VERSION ""

NS_ :

BS_:

BU_: ETH

BO_ 1824 DAS_debug: 12 Vector__XXX
 SG_ DAS_debugMultiplexer M : 0|8@1+ (1,0) [0|0] "" Vector__XXX
 SG_ DAS_ACC_Control_targetID m28 : 8|4@1+ (1,0) [0|0] "" Vector__XXX
 SG_ DAS_ACC_Restrict_targetID m29 : 8|4@1+ (1,0) [0|0] "" Vector__XXX
 SG_ DAS_ACC_Target6_dist m27 : 8|10@1+ (0.2,0) [0|0] "" Vector__XXX
 SG_ DAS_ACC_camCIPVRadObjID m21 : 8|8@1+ (1,0) [0|0] "" Vector__XXX
 SG_ DAS_ACC_intState m20 : 8|4@1+ (1,0) [0|0] "" Vector__XXX
 SG_ DAS_ACC_tgt_cipv2_dist m23 : 8|10@1+ (0.2,0) [0|0] "" Vector__XXX
 SG_ DAS_ACC_tgt_cipv_dist m22 : 8|10@1+ (0.2,0) [0|0] "" Vector__XXX
 SG_ DAS_ACC_tgt_cutin_dist m26 : 8|10@1+ (0.2,0) [0|0] "" Vector__XXX
 SG_ DAS_ACC_tgt_mcvl_dist m24 : 8|10@1+ (0.2,0) [0|0] "" Vector__XXX
 SG_ DAS_ACC_tgt_mcvr_dist m25 : 8|10@1+ (0.2,0) [0|0] "" Vector__XXX
 SG_ DAS_FCM_CIPV_distance m30 : 8|12@1+ (0.0625,0) [0|0] "" Vector__XXX
 SG_ DAS_FCM_DBG_cam_dist m35 : 8|12@1+ (0.0625,0) [0|0] "" Vector__XXX
 SG_ DAS_FCM_MCP_distance m31 : 8|12@1+ (0.0625,0) [0|0] "" Vector__XXX
 SG_ DAS_FCM_SL_distance m32 : 8|12@1+ (0.0625,0) [0|0] "" Vector__XXX
 SG_ DAS_FCM_TA_collisionStage m33 : 8|2@1+ (1,0) [0|0] "" Vector__XXX
 SG_ DAS_HmViewRangeActivationCtr m41 : 8|7@1+ (1,0) [0|0] "" Vector__XXX
 SG_ DAS_IDF_checkSensors m36 : 8|1@1+ (1,0) [0|0] "" Vector__XXX
 SG_ DAS_LCM_CIPV_ax m38 : 8|8@1- (0.1,0) [0|0] "" Vector__XXX
 SG_ DAS_LCM_CIPV_dx m37 : 8|12@1+ (0.0625,0) [0|0] "" Vector__XXX
 SG_ DAS_LCM_driver_reaction_time m39 : 8|4@1+ (0.1,0.8) [0|0] "" Vector__XXX
 SG_ DAS_LC_SteeringOffsetEstimate m42 : 8|8@1- (0.1,0) [0|0] "" Vector__XXX
 SG_ DAS_LC_VirtualLaneViewRange m40 : 8|10@1+ (0.5,0) [0|0] "" Vector__XXX
 SG_ DAS_PMM_ussConfidence m11 : 8|8@1+ (1,0) [0|0] "" Vector__XXX
 SG_ DAS_Planner_viewRange m46 : 8|9@1+ (0.5,0) [0|0] "" Vector__XXX
 SG_ DAS_SCA_state m45 : 8|3@1+ (1,0) [0|0] "" Vector__XXX
 SG_ DAS_SP_cMin m7 : 8|8@1+ (0.0025,-0.32) [0|0] "" Vector__XXX
 SG_ DAS_SP_sprecordX m9 : 8|12@1+ (0.01,-20.48) [0|0] "" Vector__XXX
 SG_ DAS_SP_vehPosX m8 : 8|12@1+ (0.01,-20.48) [0|0] "" Vector__XXX
 SG_ DAS_Stop_Sign_dist m4 : 8|11@1+ (0.1,-50) [0|0] "" Vector__XXX
 SG_ DAS_VL_HPP_rejectCounter m50 : 8|1@1+ (1,0) [0|0] "" Vector__XXX
 SG_ DAS_VL_M_LL_crossCheck m51 : 8|1@1+ (1,0) [0|0] "" Vector__XXX
 SG_ DAS_VL_exitChecks_EGO_LNE_LEFT m52 : 8|1@1+ (1,0) [0|0] "" Vector__XXX
 SG_ DAS_VWall_Left_ultra_dist m43 : 8|9@1+ (0.01,0) [0|0] "" Vector__XXX
 SG_ DAS_VWall_Right_type m44 : 8|3@1+ (1,0) [0|0] "" Vector__XXX
 SG_ DAS_apcIntState m6 : 8|4@1+ (1,0) [0|0] "" Vector__XXX
 SG_ DAS_autoWipersNetwork m60 : 8|16@1+ (0.01,0) [0|0] "" Vector__XXX
 SG_ DAS_autofixStatus m1 : 8|2@1+ (1,0) [0|0] "" Vector__XXX
 SG_ DAS_csa_accel_max m47 : 8|8@1+ (0.08,-10.24) [0|0] "" Vector__XXX
 SG_ DAS_csa_internal_state m48 : 8|4@1+ (1,0) [0|0] "" Vector__XXX
 SG_ DAS_dbg_msg_count m10 : 8|8@1+ (1,0) [0|0] "" Vector__XXX
 SG_ DAS_eyeQMode m0 : 8|8@1+ (1,0) [0|0] "" Vector__XXX
 SG_ DAS_freespaceLeftC0 m2 : 8|8@1+ (0.1,-12.8) [0|0] "" Vector__XXX
 SG_ DAS_highestSeqRcvd m3 : 8|12@1+ (1,0) [0|0] "" Vector__XXX
 SG_ DAS_i2c_dev_reg m12 : 8|8@1+ (1,0) [0|0] "" Vector__XXX
 SG_ DAS_tbt_filtered m5 : 8|12@1+ (0.01,-20.5) [0|0] "" Vector__XXX
 SG_ DAS_IDF_checkClass m36 : 9|1@1+ (1,0) [0|0] "" Vector__XXX
 SG_ DAS_VL_M_RL_crossCheck m51 : 9|1@1+ (1,0) [0|0] "" Vector__XXX
 SG_ DAS_VL_exitChecks_EGO_LNE_RGHT m52 : 9|1@1+ (1,0) [0|0] "" Vector__XXX
 SG_ DAS_FCM_TA_collisionOverlap m33 : 10|6@1+ (0.1,0) [0|0] "" Vector__XXX
 SG_ DAS_IDF_checkOverlap m36 : 10|1@1+ (1,0) [0|0] "" Vector__XXX
 SG_ DAS_VL_M_HPP_crossCheck m51 : 10|1@1+ (1,0) [0|0] "" Vector__XXX
 SG_ DAS_VL_exitChecks_BLINKER_LEFT m52 : 10|1@1+ (1,0) [0|0] "" Vector__XXX
 SG_ DAS_IDF_checkTimeToCollision m36 : 11|1@1+ (1,0) [0|0] "" Vector__XXX
 SG_ DAS_VL_M_NAV_crossCheck m51 : 11|1@1+ (1,0) [0|0] "" Vector__XXX
 SG_ DAS_VL_exitChecks_BLINKER_RGHT m52 : 11|1@1+ (1,0) [0|0] "" Vector__XXX
 SG_ DAS_ACC_Control_sl_d m28 : 12|10@1+ (0.2,0) [0|0] "" Vector__XXX
 SG_ DAS_ACC_Restrict_sl_d m29 : 12|10@1+ (0.2,0) [0|0] "" Vector__XXX
 SG_ DAS_ACC_camCIPVStatus m20 : 12|3@1+ (1,0) [0|0] "" Vector__XXX
 SG_ DAS_IDF_checkTargetProbability m36 : 12|1@1+ (1,0) [0|0] "" Vector__XXX
 SG_ DAS_LCM_override_stw_angle m39 : 12|1@1+ (1,0) [0|0] "" Vector__XXX
 SG_ DAS_SCA_angleActive m45 : 12|1@1+ (1,0) [0|0] "" Vector__XXX
 SG_ DAS_SP_distance m6 : 12|12@1+ (1,0) [0|0] "" Vector__XXX
 SG_ DAS_VL_M_V1_crossCheck m51 : 12|1@1+ (1,0) [0|0] "" Vector__XXX
 SG_ DAS_calType m1 : 12|4@1+ (1,0) [0|0] "" Vector__XXX
 SG_ DAS_pp_lanechange_fwdObst m48 : 12|1@1+ (1,0) [0|0] "" Vector__XXX
 SG_ DAS_IDF_checkSteeringAvoidance m36 : 13|1@1+ (1,0) [0|0] "" Vector__XXX
 SG_ DAS_LCM_override_stw_rate m39 : 13|1@1+ (1,0) [0|0] "" Vector__XXX
 SG_ DAS_SCA_egoRightOfCenter m45 : 13|1@1+ (1,0) [0|0] "" Vector__XXX
 SG_ DAS_VL_M_V2_crossCheck m51 : 13|1@1+ (1,0) [0|0] "" Vector__XXX
 SG_ DAS_VL_leftFsParallelLeftLane m50 : 13|1@1+ (1,0) [0|0] "" Vector__XXX
 SG_ DAS_pp_lanechange_inputsValid m48 : 13|1@1+ (1,0) [0|0] "" Vector__XXX
 SG_ DAS_IDF_checkBrakingAvoidance m36 : 14|1@1+ (1,0) [0|0] "" Vector__XXX
 SG_ DAS_LCM_override_accelerator m39 : 14|1@1+ (1,0) [0|0] "" Vector__XXX
 SG_ DAS_SCA_egoLeftOfCenter m45 : 14|1@1+ (1,0) [0|0] "" Vector__XXX
 SG_ DAS_VL_M_V3_crossCheck m51 : 14|1@1+ (1,0) [0|0] "" Vector__XXX
 SG_ DAS_VL_leftFsParallelRightLane m50 : 14|1@1+ (1,0) [0|0] "" Vector__XXX
 SG_ DAS_pp_lanechange_side m48 : 14|2@1+ (1,0) [0|0] "" Vector__XXX
 SG_ DAS_ACC_radCIPVStatus m20 : 15|3@1+ (1,0) [0|0] "" Vector__XXX
 SG_ DAS_IDF_checkEgoSpeed m36 : 15|1@1+ (1,0) [0|0] "" Vector__XXX
 SG_ DAS_LCM_override_brake m39 : 15|1@1+ (1,0) [0|0] "" Vector__XXX
 SG_ DAS_SCA_egoMovingLeft m45 : 15|1@1+ (1,0) [0|0] "" Vector__XXX
 SG_ DAS_SYNC_EyeQGlobalFrameNum m100 : 15|32@0+ (1,0) [0|0] "" Vector__XXX
 SG_ DAS_VL_M_V4_crossCheck m51 : 15|1@1+ (1,0) [0|0] "" Vector__XXX
 SG_ DAS_VL_rightFsParallelLeftLane m50 : 15|1@1+ (1,0) [0|0] "" Vector__XXX
 SG_ DAS_ACC_camCIPVRadMatchConf m21 : 16|4@1+ (1,0) [0|0] "" Vector__XXX
 SG_ DAS_FCM_state m33 : 16|8@1+ (1,0) [0|0] "" Vector__XXX
 SG_ DAS_HmGeneralActivationCtr m41 : 16|7@1+ (1,0) [0|0] "" Vector__XXX
 SG_ DAS_IDF_timeToCollision m36 : 16|8@1+ (10,0) [0|0] "" Vector__XXX
 SG_ DAS_LCM_CIPV_ay m38 : 16|8@1- (0.1,0) [0|0] "" Vector__XXX
 SG_ DAS_LCM_override_blinker m39 : 16|1@1+ (1,0) [0|0] "" Vector__XXX
 SG_ DAS_PMM_ussDistance m11 : 16|8@1+ (1,0) [0|0] "" Vector__XXX
 SG_ DAS_SCA_TWC_Left m45 : 16|8@1+ (0.01,0) [0|0] "" Vector__XXX
 SG_ DAS_SP_cMax m7 : 16|8@1+ (0.0025,-0.32) [0|0] "" Vector__XXX
 SG_ DAS_VL_M_V5_crossCheck m51 : 16|1@1+ (1,0) [0|0] "" Vector__XXX
 SG_ DAS_VL_rightFsParallelRightLane m50 : 16|1@1+ (1,0) [0|0] "" Vector__XXX
 SG_ DAS_VWall_Right_ultra_dist m44 : 16|9@1+ (0.01,0) [0|0] "" Vector__XXX
 SG_ DAS_absoluteFrame m0 : 16|32@1+ (1,0) [0|0] "" Vector__XXX
 SG_ DAS_autofixHorizon m1 : 16|8@1- (1,0) [0|0] "" Vector__XXX
 SG_ DAS_csa_predictedLatAccel m47 : 16|8@1+ (0.08,-10.24) [0|0] "" Vector__XXX
 SG_ DAS_dbg_image_data m10 : 16|48@1+ (1,0) [0|0] "" Vector__XXX
 SG_ DAS_freespaceLeftC1 m2 : 16|8@1+ (0.0016,-0.2) [0|0] "" Vector__XXX
 SG_ DAS_i2c_dev_data m12 : 16|8@1+ (1,0) [0|0] "" Vector__XXX
 SG_ DAS_pp_laneChange_destLanesValid m48 : 16|1@1+ (1,0) [0|0] "" Vector__XXX
 SG_ DAS_pp_offset_objectStateLeft m49 : 16|3@1+ (1,0) [0|0] "" Vector__XXX
 SG_ DAS_LCM_override_accelerator_aeb m39 : 17|1@1+ (1,0) [0|0] "" Vector__XXX
 SG_ DAS_Planner_internalstate m46 : 17|4@1+ (1,0) [0|0] "" Vector__XXX
 SG_ DAS_VL_LL_RL_crossCheck m51 : 17|1@1+ (1,0) [0|0] "" Vector__XXX
 SG_ DAS_VL_LL_quality m50 : 17|1@1+ (1,0) [0|0] "" Vector__XXX
 SG_ DAS_pp_laneChange_egoLaneValid m48 : 17|1@1+ (1,0) [0|0] "" Vector__XXX
 SG_ DAS_ACC_Target6_camID m27 : 18|6@1+ (1,0) [0|0] "" Vector__XXX
 SG_ DAS_ACC_radObstacleRelevant m20 : 18|1@1+ (1,0) [0|0] "" Vector__XXX
 SG_ DAS_ACC_tgt_cipv2_camID m23 : 18|6@1+ (1,0) [0|0] "" Vector__XXX
 SG_ DAS_ACC_tgt_cipv_camID m22 : 18|6@1+ (1,0) [0|0] "" Vector__XXX
 SG_ DAS_ACC_tgt_cutin_camID m26 : 18|6@1+ (1,0) [0|0] "" Vector__XXX
 SG_ DAS_ACC_tgt_mcvl_camID m24 : 18|6@1+ (1,0) [0|0] "" Vector__XXX
 SG_ DAS_ACC_tgt_mcvr_camID m25 : 18|6@1+ (1,0) [0|0] "" Vector__XXX
 SG_ DAS_LCM_override_brake_aeb m39 : 18|1@1+ (1,0) [0|0] "" Vector__XXX
 SG_ DAS_LC_VirtualLaneWidth m40 : 18|8@1+ (0.025,0) [0|0] "" Vector__XXX
 SG_ DAS_VL_LL_HPP_crossCheck m51 : 18|1@1+ (1,0) [0|0] "" Vector__XXX
 SG_ DAS_VL_RL_quality m50 : 18|1@1+ (1,0) [0|0] "" Vector__XXX
 SG_ DAS_pp_laneChange_anyObstacle m48 : 18|1@1+ (1,0) [0|0] "" Vector__XXX
 SG_ DAS_ACC_pedestrianStatus m20 : 19|2@1+ (1,0) [0|0] "" Vector__XXX
 SG_ DAS_LCM_aeb_abs_accel m39 : 19|1@1+ (1,0) [0|0] "" Vector__XXX
 SG_ DAS_Stop_Sign_detected m4 : 19|1@1+ (1,0) [0|0] "" Vector__XXX
 SG_ DAS_VL_HPP_quality m50 : 19|1@1+ (1,0) [0|0] "" Vector__XXX
 SG_ DAS_VL_LL_NAV_crossCheck m51 : 19|1@1+ (1,0) [0|0] "" Vector__XXX
 SG_ DAS_pp_laneChange_closeObstacle m48 : 19|1@1+ (1,0) [0|0] "" Vector__XXX
 SG_ DAS_pp_offset_objectStateRight m49 : 19|3@1+ (1,0) [0|0] "" Vector__XXX
 SG_ DAS_ACC_camCIPVClass m21 : 20|4@1+ (1,0) [0|0] "" Vector__XXX
 SG_ DAS_FCM_CIPV_latDistance m30 : 20|12@1- (0.05,0) [0|0] "" Vector__XXX
 SG_ DAS_FCM_DBG_cam_relvel m35 : 20|12@1+ (0.0625,-128) [0|0] "" Vector__XXX
 SG_ DAS_FCM_MCP_latDistance m31 : 20|12@1- (0.05,0) [0|0] "" Vector__XXX
 SG_ DAS_FCM_SL_latDistance m32 : 20|12@1- (0.05,0) [0|0] "" Vector__XXX
 SG_ DAS_LCM_CIPV_dy m37 : 20|12@1- (0.05,0) [0|0] "" Vector__XXX
 SG_ DAS_LCM_aeb_overlap m39 : 20|1@1+ (1,0) [0|0] "" Vector__XXX
 SG_ DAS_SP_sprecordY m9 : 20|12@1+ (0.01,-20.48) [0|0] "" Vector__XXX
 SG_ DAS_SP_vehPosY m8 : 20|12@1+ (0.01,-20.48) [0|0] "" Vector__XXX
 SG_ DAS_Stop_Sign_warning m4 : 20|1@1+ (1,0) [0|0] "" Vector__XXX
 SG_ DAS_VL_LL_V1_crossCheck m51 : 20|1@1+ (1,0) [0|0] "" Vector__XXX
 SG_ DAS_VL_NAV_quality m50 : 20|1@1+ (1,0) [0|0] "" Vector__XXX
 SG_ DAS_errorFrameNum m3 : 20|12@1+ (1,0) [0|0] "" Vector__XXX
 SG_ DAS_pp_laneChange_LC_healthy m48 : 20|1@1+ (1,0) [0|0] "" Vector__XXX
 SG_ DAS_ACC_drivingOnHighway m20 : 21|1@1+ (1,0) [0|0] "" Vector__XXX
 SG_ DAS_LCM_aeb_current_accel m39 : 21|1@1+ (1,0) [0|0] "" Vector__XXX
 SG_ DAS_Planner_externalstate m46 : 21|4@1+ (1,0) [0|0] "" Vector__XXX
 SG_ DAS_TFL_jnc_status m4 : 21|3@1+ (1,0) [0|0] "" Vector__XXX
 SG_ DAS_VL_LL_V2_crossCheck m51 : 21|1@1+ (1,0) [0|0] "" Vector__XXX
 SG_ DAS_VL_V1_quality m50 : 21|1@1+ (1,0) [0|0] "" Vector__XXX
 SG_ DAS_pp_laneChange_blinkerCheck m48 : 21|1@1+ (1,0) [0|0] "" Vector__XXX
 SG_ DAS_ACC_Control_ve_d m28 : 22|10@1+ (0.05,0) [0|0] "" Vector__XXX
 SG_ DAS_ACC_Restrict_ve_d m29 : 22|10@1+ (0.05,0) [0|0] "" Vector__XXX
 SG_ DAS_LCM_aeb_delayed_accel m39 : 22|1@1+ (1,0) [0|0] "" Vector__XXX
 SG_ DAS_VL_LL_V3_crossCheck m51 : 22|1@1+ (1,0) [0|0] "" Vector__XXX
 SG_ DAS_VL_WidthMeasType m50 : 22|3@1+ (1,0) [0|0] "" Vector__XXX
 SG_ DAS_pp_offset_activeLeft m49 : 22|1@1+ (1,0) [0|0] "" Vector__XXX
 SG_ DAS_torque_filt_0p05Hz m48 : 22|12@1+ (0.01,-20.5) [0|0] "" Vector__XXX
 SG_ DAS_HmSecondaryVlInput m41 : 23|1@1+ (1,0) [0|0] "" Vector__XXX
 SG_ DAS_LCM_aeb_evading_dist m39 : 23|1@1+ (1,0) [0|0] "" Vector__XXX
 SG_ DAS_VL_LL_V4_crossCheck m51 : 23|1@1+ (1,0) [0|0] "" Vector__XXX
 SG_ DAS_pp_offset_activeRight m49 : 23|1@1+ (1,0) [0|0] "" Vector__XXX
 SG_ DAS_ACC_Target6_speed m27 : 24|8@1+ (0.2,-5) [0|0] "" Vector__XXX
 SG_ DAS_ACC_camCIPVRelevancy m21 : 24|4@1+ (1,0) [0|0] "" Vector__XXX
 SG_ DAS_ACC_tgt_cipv2_speed m23 : 24|8@1+ (0.2,-5) [0|0] "" Vector__XXX
 SG_ DAS_ACC_tgt_cipv_speed m22 : 24|8@1+ (0.2,-5) [0|0] "" Vector__XXX
 SG_ DAS_ACC_tgt_cutin_speed m26 : 24|8@1+ (0.2,-5) [0|0] "" Vector__XXX
 SG_ DAS_ACC_tgt_mcvl_speed m24 : 24|8@1+ (0.2,-5) [0|0] "" Vector__XXX
 SG_ DAS_ACC_tgt_mcvr_speed m25 : 24|8@1+ (0.2,-5) [0|0] "" Vector__XXX
 SG_ DAS_FCM_TA_rstCollStRsn m33 : 24|8@1+ (1,0) [0|0] "" Vector__XXX
 SG_ DAS_FCM_TA_stage2Checks m34 : 24|8@1+ (1,0) [0|0] "" Vector__XXX
 SG_ DAS_IDF_objectClass m36 : 24|3@1+ (1,0) [0|0] "" Vector__XXX
 SG_ DAS_LCM_CIPV_id m38 : 24|8@1+ (1,0) [0|0] "" Vector__XXX
 SG_ DAS_LCM_aeb_rel_vel m39 : 24|1@1+ (1,0) [0|0] "" Vector__XXX
 SG_ DAS_LC_PathFollowerAngle m42 : 24|13@1- (0.1,0) [0|0] "" Vector__XXX
 SG_ DAS_PF_Navigation_STW m41 : 24|13@1+ (0.1,-409.6) [0|0] "" Vector__XXX
 SG_ DAS_PMM_radarConfidence m11 : 24|8@1+ (1,0) [0|0] "" Vector__XXX
 SG_ DAS_SCA_TWC_Right m45 : 24|8@1+ (0.01,0) [0|0] "" Vector__XXX
 SG_ DAS_SP_instruction m6 : 24|4@1+ (1,0) [0|0] "" Vector__XXX
 SG_ DAS_SP_interCMin m7 : 24|8@1+ (0.0025,-0.32) [0|0] "" Vector__XXX
 SG_ DAS_TFL_jnc_dist m4 : 24|10@1+ (0.25,-50) [0|0] "" Vector__XXX
 SG_ DAS_VL_LL_V5_crossCheck m51 : 24|1@1+ (1,0) [0|0] "" Vector__XXX
 SG_ DAS_autoWipersPerMinute m60 : 24|8@1+ (1,0) [0|0] "" Vector__XXX
 SG_ DAS_autofixYaw m1 : 24|8@1- (1,0) [0|0] "" Vector__XXX
 SG_ DAS_csa_filteredCurvature m47 : 24|16@1- (1e-06,0) [0|0] "" Vector__XXX
 SG_ DAS_freespaceRightC0 m2 : 24|8@1+ (0.1,-12.8) [0|0] "" Vector__XXX
 SG_ DAS_i2c_cmd_idx m12 : 24|16@1+ (1,0) [0|0] "" Vector__XXX
 SG_ DAS_pp_offset_offsetObjectLeft m49 : 24|8@1- (0.01,0) [0|0] "" Vector__XXX
 SG_ DAS_LCM_jerk_abs_accel m39 : 25|1@1+ (1,0) [0|0] "" Vector__XXX
 SG_ DAS_VL_RL_HPP_crossCheck m51 : 25|1@1+ (1,0) [0|0] "" Vector__XXX
 SG_ DAS_VL_Reinitialized m50 : 25|1@1+ (1,0) [0|0] "" Vector__XXX
 SG_ DAS_ACC_Ego_speed m20 : 26|10@1+ (0.05,0) [0|0] "" Vector__XXX
 SG_ DAS_LCM_jerk_overlap m39 : 26|1@1+ (1,0) [0|0] "" Vector__XXX
 SG_ DAS_LC_AutopilotInternalState m40 : 26|4@1+ (1,0) [0|0] "" Vector__XXX
 SG_ DAS_VL_LL_rejectQuality m50 : 26|1@1+ (1,0) [0|0] "" Vector__XXX
 SG_ DAS_VL_RL_NAV_crossCheck m51 : 26|1@1+ (1,0) [0|0] "" Vector__XXX
 SG_ DAS_IDF_predictedImpactVelocity m36 : 27|7@1+ (0.5,0) [0|0] "" Vector__XXX
 SG_ DAS_LCM_jerk_current_accel m39 : 27|1@1+ (1,0) [0|0] "" Vector__XXX
 SG_ DAS_VL_LL_rejectType m50 : 27|1@1+ (1,0) [0|0] "" Vector__XXX
 SG_ DAS_VL_RL_V1_crossCheck m51 : 27|1@1+ (1,0) [0|0] "" Vector__XXX
 SG_ DAS_ACC_camCIPVLane m21 : 28|4@1+ (1,0) [0|0] "" Vector__XXX
 SG_ DAS_LCM_jerk_delayed_accel m39 : 28|1@1+ (1,0) [0|0] "" Vector__XXX
 SG_ DAS_SP_status m6 : 28|4@1+ (1,0) [0|0] "" Vector__XXX
 SG_ DAS_VL_LL_rejectRange m50 : 28|1@1+ (1,0) [0|0] "" Vector__XXX
 SG_ DAS_VL_RL_V2_crossCheck m51 : 28|1@1+ (1,0) [0|0] "" Vector__XXX
 SG_ DAS_LCM_jerk_evading_dist m39 : 29|1@1+ (1,0) [0|0] "" Vector__XXX
 SG_ DAS_VL_LL_rejectFreespace m50 : 29|1@1+ (1,0) [0|0] "" Vector__XXX
 SG_ DAS_VL_RL_V3_crossCheck m51 : 29|1@1+ (1,0) [0|0] "" Vector__XXX
 SG_ DAS_LCM_jerk_rel_vel m39 : 30|1@1+ (1,0) [0|0] "" Vector__XXX
 SG_ DAS_LC_Speed_Ctrl_Active m40 : 30|1@1+ (1,0) [0|0] "" Vector__XXX
 SG_ DAS_VL_LL_rejectDyingLine m50 : 30|1@1+ (1,0) [0|0] "" Vector__XXX
 SG_ DAS_VL_RL_V4_crossCheck m51 : 30|1@1+ (1,0) [0|0] "" Vector__XXX
 SG_ DAS_LCM_fcw_abs_accel m39 : 31|1@1+ (1,0) [0|0] "" Vector__XXX
 SG_ DAS_LC_Crit_Left_Lane m40 : 31|8@1+ (0.2,-25.5) [0|0] "" Vector__XXX
 SG_ DAS_VL_LL_rejectLatDiffAtCP m50 : 31|1@1+ (1,0) [0|0] "" Vector__XXX
 SG_ DAS_VL_RL_V5_crossCheck m51 : 31|1@1+ (1,0) [0|0] "" Vector__XXX
 SG_ DAS_ACC_Control_severity m28 : 32|10@1+ (0.005,-2.56) [0|0] "" Vector__XXX
 SG_ DAS_ACC_Restrict_severity m29 : 32|10@1+ (0.005,-2.56) [0|0] "" Vector__XXX
 SG_ DAS_ACC_camCIPVLaneStatus m21 : 32|4@1+ (1,0) [0|0] "" Vector__XXX
 SG_ DAS_ACC_tgt_cipv2_radID m23 : 32|6@1+ (1,0) [0|0] "" Vector__XXX
 SG_ DAS_ACC_tgt_cipv_radID m22 : 32|6@1+ (1,0) [0|0] "" Vector__XXX
 SG_ DAS_ACC_tgt_cutin_radID m26 : 32|6@1+ (1,0) [0|0] "" Vector__XXX
 SG_ DAS_ACC_tgt_mcvl_radID m24 : 32|6@1+ (1,0) [0|0] "" Vector__XXX
 SG_ DAS_ACC_tgt_mcvr_radID m25 : 32|6@1+ (1,0) [0|0] "" Vector__XXX
 SG_ DAS_FCM_CIPV_width m30 : 32|7@1+ (0.05,0) [0|0] "" Vector__XXX
 SG_ DAS_FCM_DBG_probability m35 : 32|6@1+ (0.05,0) [0|0] "" Vector__XXX
 SG_ DAS_FCM_MCP_width m31 : 32|7@1+ (0.05,0) [0|0] "" Vector__XXX
 SG_ DAS_FCM_SL_width m32 : 32|7@1+ (0.05,0) [0|0] "" Vector__XXX
 SG_ DAS_FCM_TA_reqAccelDrvr m33 : 32|7@1+ (0.1,-12.7) [0|0] "" Vector__XXX
 SG_ DAS_FCM_TA_stage3Checks m34 : 32|8@1+ (1,0) [0|0] "" Vector__XXX
 SG_ DAS_LCM_CIPV_track_age m38 : 32|12@1+ (0.01,0) [0|0] "" Vector__XXX
 SG_ DAS_LCM_CIPV_width m37 : 32|8@1+ (0.05,0) [0|0] "" Vector__XXX
 SG_ DAS_LCM_fcw_overlap m39 : 32|1@1+ (1,0) [0|0] "" Vector__XXX
 SG_ DAS_PMM_radarDistance m11 : 32|8@1+ (1,0) [0|0] "" Vector__XXX
 SG_ DAS_Planner_c0 m46 : 32|8@1- (0.1,0) [0|0] "" Vector__XXX
 SG_ DAS_SP_autoSummonRequest m6 : 32|1@1+ (1,0) [0|0] "" Vector__XXX
 SG_ DAS_SP_collisionDist m9 : 32|12@1+ (0.01,-20.48) [0|0] "" Vector__XXX
 SG_ DAS_SP_endPosX m8 : 32|12@1+ (0.01,-20.48) [0|0] "" Vector__XXX
 SG_ DAS_SP_interCMax m7 : 32|8@1+ (0.0025,-0.32) [0|0] "" Vector__XXX
 SG_ DAS_VL_HPP_NAV_crossCheck m51 : 32|1@1+ (1,0) [0|0] "" Vector__XXX
 SG_ DAS_VL_LL_rejectPrediction m50 : 32|1@1+ (1,0) [0|0] "" Vector__XXX
 SG_ DAS_VWall_Right_c0 m44 : 32|8@1+ (0.035,0) [0|0] "" Vector__XXX
 SG_ DAS_autoWipersValid m60 : 32|1@1+ (1,0) [0|0] "" Vector__XXX
 SG_ DAS_freespaceRightC1 m2 : 32|8@1+ (0.0016,-0.2) [0|0] "" Vector__XXX
 SG_ DAS_numOfOldPktErrs m3 : 32|8@1+ (1,0) [0|0] "" Vector__XXX
 SG_ DAS_pp_offset_offsetObjectRight m49 : 32|8@1- (0.01,0) [0|0] "" Vector__XXX
 SG_ DAS_torque_filt_0p5Hz m45 : 32|12@1+ (0.01,-20.5) [0|0] "" Vector__XXX
 SG_ DAS_LCM_fcw_current_accel m39 : 33|1@1+ (1,0) [0|0] "" Vector__XXX
 SG_ DAS_VL_HPP_V1_crossCheck m51 : 33|1@1+ (1,0) [0|0] "" Vector__XXX
 SG_ DAS_VL_LL_rejectHWExit m50 : 33|1@1+ (1,0) [0|0] "" Vector__XXX
 SG_ DAS_estimatedSpeedLimitType m6 : 33|3@1+ (1,0) [0|0] "" Vector__XXX
 SG_ DAS_ACC_Target6_radID m27 : 34|6@1+ (1,0) [0|0] "" Vector__XXX
 SG_ DAS_IDF_predictedOverlap m36 : 34|8@1+ (0.5,0) [0|0] "" Vector__XXX
 SG_ DAS_LCM_fcw_delayed_accel m39 : 34|1@1+ (1,0) [0|0] "" Vector__XXX
 SG_ DAS_TFL_stop_line_dist m4 : 34|11@1+ (0.1,-50) [0|0] "" Vector__XXX
 SG_ DAS_VL_HPP_V2_crossCheck m51 : 34|1@1+ (1,0) [0|0] "" Vector__XXX
 SG_ DAS_VL_LL_rejectCounter m50 : 34|1@1+ (1,0) [0|0] "" Vector__XXX
 SG_ DAS_csa_using_offramp m48 : 34|1@1+ (1,0) [0|0] "" Vector__XXX
 SG_ DAS_LCM_fcw_evading_dist m39 : 35|1@1+ (1,0) [0|0] "" Vector__XXX
 SG_ DAS_VL_HPP_V3_crossCheck m51 : 35|1@1+ (1,0) [0|0] "" Vector__XXX
 SG_ DAS_VL_RL_rejectQuality m50 : 35|1@1+ (1,0) [0|0] "" Vector__XXX
 SG_ DAS_csa_using_frozen_offramp m48 : 35|1@1+ (1,0) [0|0] "" Vector__XXX
 SG_ DAS_ACC_Ego_accel m20 : 36|8@1+ (0.06,-10) [0|0] "" Vector__XXX
 SG_ DAS_ACC_camCIPVBrakeLight m21 : 36|4@1+ (1,0) [0|0] "" Vector__XXX
 SG_ DAS_LCM_fcw_rel_vel m39 : 36|1@1+ (1,0) [0|0] "" Vector__XXX
 SG_ DAS_VL_HPP_V4_crossCheck m51 : 36|1@1+ (1,0) [0|0] "" Vector__XXX
 SG_ DAS_VL_RL_rejectType m50 : 36|1@1+ (1,0) [0|0] "" Vector__XXX
 SG_ DAS_csa_mpp_jumped_up m48 : 36|1@1+ (1,0) [0|0] "" Vector__XXX
 SG_ DAS_LCM_state m39 : 37|4@1+ (1,0) [0|0] "" Vector__XXX
 SG_ DAS_PF_VirtualLane_STW m41 : 37|13@1+ (0.1,-409.6) [0|0] "" Vector__XXX
 SG_ DAS_VL_HPP_V5_crossCheck m51 : 37|1@1+ (1,0) [0|0] "" Vector__XXX
 SG_ DAS_VL_RL_rejectRange m50 : 37|1@1+ (1,0) [0|0] "" Vector__XXX
 SG_ DAS_csa_mpp_jump_up_distance m48 : 37|8@1+ (10,0) [0|0] "" Vector__XXX
 SG_ DAS_ACC_tgt_cipv2_accel m23 : 38|8@1+ (0.06,-10) [0|0] "" Vector__XXX
 SG_ DAS_ACC_tgt_cipv_accel m22 : 38|8@1+ (0.06,-10) [0|0] "" Vector__XXX
 SG_ DAS_ACC_tgt_cutin_accel m26 : 38|8@1+ (0.06,-10) [0|0] "" Vector__XXX
 SG_ DAS_ACC_tgt_mcvl_accel m24 : 38|8@1+ (0.06,-10) [0|0] "" Vector__XXX
 SG_ DAS_ACC_tgt_mcvr_accel m25 : 38|8@1+ (0.06,-10) [0|0] "" Vector__XXX
 SG_ DAS_FCM_DBG_trust m35 : 38|6@1+ (0.05,0) [0|0] "" Vector__XXX
 SG_ DAS_VL_NAV_V1_crossCheck m51 : 38|1@1+ (1,0) [0|0] "" Vector__XXX
 SG_ DAS_VL_RL_rejectFreespace m50 : 38|1@1+ (1,0) [0|0] "" Vector__XXX
 SG_ DAS_FCM_CIPV_relSpeed m30 : 39|12@1+ (0.0625,-128) [0|0] "" Vector__XXX
 SG_ DAS_FCM_MCP_relSpeed m31 : 39|12@1+ (0.0625,-128) [0|0] "" Vector__XXX
 SG_ DAS_FCM_SL_relSpeed m32 : 39|12@1+ (0.0625,-128) [0|0] "" Vector__XXX
 SG_ DAS_FCM_TA_reqAccelAeb m33 : 39|7@1+ (0.1,-12.7) [0|0] "" Vector__XXX
 SG_ DAS_VL_NAV_V2_crossCheck m51 : 39|1@1+ (1,0) [0|0] "" Vector__XXX
 SG_ DAS_VL_RL_rejectDyingLine m50 : 39|1@1+ (1,0) [0|0] "" Vector__XXX
 SG_ DAS_rampType m6 : 39|2@1+ (1,0) [0|0] "" Vector__XXX
 SG_ DAS_ACC_Target6_accel m27 : 40|8@1+ (0.06,-10) [0|0] "" Vector__XXX
 SG_ DAS_ACC_camCIPVMotionStatus m21 : 40|4@1+ (1,0) [0|0] "" Vector__XXX
 SG_ DAS_FCM_DBG_suppressed m34 : 40|1@1+ (1,0) [0|0] "" Vector__XXX
 SG_ DAS_HmLaneViewRangeOAL m42 : 40|3@1+ (1,0) [0|0] "" Vector__XXX
 SG_ DAS_LCM_CIPV_vx m37 : 40|12@1- (0.0625,0) [0|0] "" Vector__XXX
 SG_ DAS_PMM_totalThreat m11 : 40|8@1+ (1,0) [0|0] "" Vector__XXX
 SG_ DAS_Planner_c1 m46 : 40|8@1+ (0.0016,-0.2) [0|0] "" Vector__XXX
 SG_ DAS_SP_cDesired m7 : 40|8@1+ (0.0025,-0.32) [0|0] "" Vector__XXX
 SG_ DAS_VL_NAV_V3_crossCheck m51 : 40|1@1+ (1,0) [0|0] "" Vector__XXX
 SG_ DAS_VL_RL_rejectLatDiffAtCP m50 : 40|1@1+ (1,0) [0|0] "" Vector__XXX
 SG_ DAS_VWall_Right_c1 m44 : 40|8@1+ (0.0016,-0.2) [0|0] "" Vector__XXX
 SG_ DAS_csa_desiredVelPred m47 : 40|8@1+ (0.29,15) [0|0] "" Vector__XXX
 SG_ DAS_freespaceLeftFarZ m2 : 40|4@1+ (4,0) [0|0] "" Vector__XXX
 SG_ DAS_i2c_bytes_written m12 : 40|8@1+ (1,0) [0|0] "" Vector__XXX
 SG_ DAS_numOfSeqErrs m3 : 40|8@1+ (1,0) [0|0] "" Vector__XXX
 SG_ DAS_pp_offset_objDurationLeft m49 : 40|8@1+ (4,0) [0|0] "" Vector__XXX
 SG_ DAS_FCM_DBG_me_flag m34 : 41|1@1+ (1,0) [0|0] "" Vector__XXX
 SG_ DAS_LCM_required_system_accel m39 : 41|7@1- (0.20158730158730157,-6.249206349206348) [0|0] "" Vector__XXX
 SG_ DAS_VL_NAV_V4_crossCheck m51 : 41|1@1+ (1,0) [0|0] "" Vector__XXX
 SG_ DAS_VL_RL_rejectPrediction m50 : 41|1@1+ (1,0) [0|0] "" Vector__XXX
 SG_ DAS_estimatedSpeedLimit m6 : 41|10@1+ (0.2,0) [0|0] "" Vector__XXX
 SG_ DAS_ACC_Control_deltaV_deriv m28 : 42|10@1+ (0.01,-5) [0|0] "" Vector__XXX
 SG_ DAS_ACC_Restrict_deltaV_deriv m29 : 42|10@1+ (0.01,-5) [0|0] "" Vector__XXX
 SG_ DAS_IDF_checkImpactVelocity m36 : 42|1@1+ (1,0) [0|0] "" Vector__XXX
 SG_ DAS_VL_NAV_V5_crossCheck m51 : 42|1@1+ (1,0) [0|0] "" Vector__XXX
 SG_ DAS_VL_RL_rejectHWExit m50 : 42|1@1+ (1,0) [0|0] "" Vector__XXX
 SG_ DAS_FCM_DBG_aeb_cancel m34 : 43|1@1+ (1,0) [0|0] "" Vector__XXX
 SG_ DAS_IDF_checkCameraTTC m36 : 43|1@1+ (1,0) [0|0] "" Vector__XXX
 SG_ DAS_VL_RL_rejectCounter m50 : 43|1@1+ (1,0) [0|0] "" Vector__XXX
 SG_ DAS_VL_V1_V2_crossCheck m51 : 43|1@1+ (1,0) [0|0] "" Vector__XXX
 SG_ DAS_ACC_camCIPVLost m21 : 44|2@1+ (1,0) [0|0] "" Vector__XXX
 SG_ DAS_ACC_deadbandMultiplier m20 : 44|7@1+ (0.008,0) [0|0] "" Vector__XXX
 SG_ DAS_FCM_DBG_aeb_fault m34 : 44|1@1+ (1,0) [0|0] "" Vector__XXX
 SG_ DAS_FCM_DBG_rvl_check m35 : 44|6@1+ (0.05,0) [0|0] "" Vector__XXX
 SG_ DAS_IDF_checkLateralAcceleration m36 : 44|1@1+ (1,0) [0|0] "" Vector__XXX
 SG_ DAS_LCM_CIPV_overlap m38 : 44|8@1- (0.05,0.05) [0|0] "" Vector__XXX
 SG_ DAS_SP_endPosY m8 : 44|12@1+ (0.01,-20.48) [0|0] "" Vector__XXX
 SG_ DAS_VL_HPP_rejectError m50 : 44|1@1+ (1,0) [0|0] "" Vector__XXX
 SG_ DAS_VL_V1_V3_crossCheck m51 : 44|1@1+ (1,0) [0|0] "" Vector__XXX
 SG_ DAS_freespaceRightFarZ m2 : 44|4@1+ (4,0) [0|0] "" Vector__XXX
 SG_ DAS_hands_on_detected m45 : 44|1@1+ (1,0) [0|0] "" Vector__XXX
 SG_ DAS_FCM_DBG_ACC1_fused m34 : 45|1@1+ (1,0) [0|0] "" Vector__XXX
 SG_ DAS_IDF_measurementState m36 : 45|2@1+ (1,0) [0|0] "" Vector__XXX
 SG_ DAS_TBT_offset m45 : 45|11@1+ (0.001,-1) [0|0] "" Vector__XXX
 SG_ DAS_TFL_ttc m4 : 45|9@1+ (0.01,0) [0|0] "" Vector__XXX
 SG_ DAS_VL_HPP_rejectRange m50 : 45|1@1+ (1,0) [0|0] "" Vector__XXX
 SG_ DAS_VL_V1_V4_crossCheck m51 : 45|1@1+ (1,0) [0|0] "" Vector__XXX
 SG_ DAS_csa_offramp_usage_duration m48 : 45|8@1+ (256,0) [0|0] "" Vector__XXX
 SG_ DAS_ACC_camCIPVFreeSpace m21 : 46|2@1+ (1,0) [0|0] "" Vector__XXX
 SG_ DAS_ACC_tgt_cipv2_controlState m23 : 46|4@1+ (1,0) [0|0] "" Vector__XXX
 SG_ DAS_ACC_tgt_cipv_controlState m22 : 46|4@1+ (1,0) [0|0] "" Vector__XXX
 SG_ DAS_ACC_tgt_cutin_controlState m26 : 46|4@1+ (1,0) [0|0] "" Vector__XXX
 SG_ DAS_ACC_tgt_mcvl_controlState m24 : 46|4@1+ (1,0) [0|0] "" Vector__XXX
 SG_ DAS_ACC_tgt_mcvr_controlState m25 : 46|4@1+ (1,0) [0|0] "" Vector__XXX
 SG_ DAS_FCM_DBG_ACC5_fused m34 : 46|1@1+ (1,0) [0|0] "" Vector__XXX
 SG_ DAS_FCM_TA_distDiffSteerDrvr m33 : 46|8@1+ (0.1,0) [0|0] "" Vector__XXX
 SG_ DAS_VL_HPP_rejectWiper m50 : 46|1@1+ (1,0) [0|0] "" Vector__XXX
 SG_ DAS_VL_V1_V5_crossCheck m51 : 46|1@1+ (1,0) [0|0] "" Vector__XXX
 SG_ DAS_FCM_DBG_ID m34 : 47|16@1+ (1,0) [0|0] "" Vector__XXX
 SG_ DAS_LCM_aeb_unavailable_reason m36 : 47|5@1+ (1,0) [0|0] "" Vector__XXX
 SG_ DAS_LC_Crit_Right_Lane m40 : 47|8@1+ (0.2,-25.5) [0|0] "" Vector__XXX
 SG_ DAS_SYNC_DASLocalTimeStamp m100 : 47|24@0+ (1,0) [0|0] "" Vector__XXX
 SG_ DAS_VL_HPP_rejectNight m50 : 47|1@1+ (1,0) [0|0] "" Vector__XXX
 SG_ DAS_VL_V2_V3_crossCheck m51 : 47|1@1+ (1,0) [0|0] "" Vector__XXX
 SG_ DAS_ACC_Target6_controlState m27 : 48|4@1+ (1,0) [0|0] "" Vector__XXX
 SG_ DAS_ACC_camStopAndGoStatus m21 : 48|2@1+ (1,0) [0|0] "" Vector__XXX
 SG_ DAS_LCM_aeb_evading_distance m39 : 48|8@1- (0.1,0.1) [0|0] "" Vector__XXX
 SG_ DAS_PMM_frontThreat m11 : 48|2@1+ (1,0) [0|0] "" Vector__XXX
 SG_ DAS_Planner_c2 m46 : 48|8@1+ (2e-05,-0.0025) [0|0] "" Vector__XXX
 SG_ DAS_VL_HPP_rejectCipvClose m50 : 48|1@1+ (1,0) [0|0] "" Vector__XXX
 SG_ DAS_VL_V2_V4_crossCheck m51 : 48|1@1+ (1,0) [0|0] "" Vector__XXX
 SG_ DAS_VWall_Right_c2 m44 : 48|8@1+ (2e-05,-0.0025) [0|0] "" Vector__XXX
 SG_ DAS_csa_measuredLatAccel m47 : 48|8@1+ (0.08,-10.24) [0|0] "" Vector__XXX
 SG_ DAS_i2c_sensor_cmd m12 : 48|16@1+ (1,0) [0|0] "" Vector__XXX
 SG_ DAS_numOfCrcErrs m3 : 48|8@1+ (1,0) [0|0] "" Vector__XXX
 SG_ DAS_pp_offset_desired m0 : 48|8@1- (0.01,0) [0|0] "" Vector__XXX
 SG_ DAS_pp_offset_objDurationRight m49 : 48|8@1+ (4,0) [0|0] "" Vector__XXX
 SG_ DAS_rawLDW m2 : 48|2@1+ (1,0) [0|0] "" Vector__XXX
 SG_ DAS_VL_NAV_rejectHealth m50 : 49|1@1+ (1,0) [0|0] "" Vector__XXX
 SG_ DAS_VL_V2_V5_crossCheck m51 : 49|1@1+ (1,0) [0|0] "" Vector__XXX
 SG_ DAS_ACC_camLeftCloseCutin m21 : 50|1@1+ (1,0) [0|0] "" Vector__XXX
 SG_ DAS_ACC_tgt_cipv2_type m23 : 50|4@1+ (1,0) [0|0] "" Vector__XXX
 SG_ DAS_ACC_tgt_cipv_type m22 : 50|4@1+ (1,0) [0|0] "" Vector__XXX
 SG_ DAS_ACC_tgt_cutin_type m26 : 50|4@1+ (1,0) [0|0] "" Vector__XXX
 SG_ DAS_ACC_tgt_mcvl_type m24 : 50|4@1+ (1,0) [0|0] "" Vector__XXX
 SG_ DAS_ACC_tgt_mcvr_type m25 : 50|4@1+ (1,0) [0|0] "" Vector__XXX
 SG_ DAS_FCM_DBG_dist_check m35 : 50|6@1+ (0.05,0) [0|0] "" Vector__XXX
 SG_ DAS_PF_PercentConsistency m41 : 50|14@1+ (0.01,0) [0|0] "" Vector__XXX
 SG_ DAS_PMM_rearThreat m11 : 50|2@1+ (1,0) [0|0] "" Vector__XXX
 SG_ DAS_VL_NAV_rejectAge m50 : 50|1@1+ (1,0) [0|0] "" Vector__XXX
 SG_ DAS_VL_V3_V4_crossCheck m51 : 50|1@1+ (1,0) [0|0] "" Vector__XXX
 SG_ DAS_freespaceLDW m2 : 50|2@1+ (1,0) [0|0] "" Vector__XXX
 SG_ DAS_ACC_camRightCloseCutin m21 : 51|1@1+ (1,0) [0|0] "" Vector__XXX
 SG_ DAS_ACC_leftLaneExists m20 : 51|1@1+ (1,0) [0|0] "" Vector__XXX
 SG_ DAS_FCM_CIPV_relAccel m30 : 51|10@1+ (0.03125,-16) [0|0] "" Vector__XXX
 SG_ DAS_FCM_MCP_relAccel m31 : 51|10@1+ (0.03125,-16) [0|0] "" Vector__XXX
 SG_ DAS_FCM_SL_relAccel m32 : 51|10@1+ (0.03125,-16) [0|0] "" Vector__XXX
 SG_ DAS_VL_NAV_rejectCounter m50 : 51|1@1+ (1,0) [0|0] "" Vector__XXX
 SG_ DAS_VL_V3_V5_crossCheck m51 : 51|1@1+ (1,0) [0|0] "" Vector__XXX
 SG_ DAS_resumeSpeed m6 : 51|10@1+ (0.2,0) [0|0] "" Vector__XXX
 SG_ DAS_ACC_Activate_healthy m28 : 52|1@1+ (1,0) [0|0] "" Vector__XXX
 SG_ DAS_ACC_Target6_type m27 : 52|4@1+ (1,0) [0|0] "" Vector__XXX
 SG_ DAS_ACC_camPedestriansPresent m21 : 52|1@1+ (1,0) [0|0] "" Vector__XXX
 SG_ DAS_ACC_rightLaneExists m20 : 52|1@1+ (1,0) [0|0] "" Vector__XXX
 SG_ DAS_LCM_CIPV_ttc m38 : 52|6@1+ (0.05,0) [0|0] "" Vector__XXX
 SG_ DAS_LCM_CIPV_vy m37 : 52|8@1- (0.1,0) [0|0] "" Vector__XXX
 SG_ DAS_LCM_fcw_unavailable_reason m36 : 52|5@1+ (1,0) [0|0] "" Vector__XXX
 SG_ DAS_LC_EgoPitchMotionRate m29 : 52|10@1+ (0.05,-25) [0|0] "" Vector__XXX
 SG_ DAS_VL_V2_quality m50 : 52|1@1+ (1,0) [0|0] "" Vector__XXX
 SG_ DAS_VL_V4_V5_crossCheck m51 : 52|1@1+ (1,0) [0|0] "" Vector__XXX
 SG_ DAS_lanesValid m2 : 52|1@1+ (1,0) [0|0] "" Vector__XXX
 SG_ DAS_ACC_Activate_travel_dist m28 : 53|1@1+ (1,0) [0|0] "" Vector__XXX
 SG_ DAS_ACC_camInFrontOfCIPVRel m20 : 53|1@1+ (1,0) [0|0] "" Vector__XXX
 SG_ DAS_ACC_pathOverlapWTarget m21 : 53|5@1+ (0.2,-2) [0|0] "" Vector__XXX
 SG_ DAS_VL_LL_fuse m51 : 53|1@1+ (1,0) [0|0] "" Vector__XXX
 SG_ DAS_VL_V3_quality m50 : 53|1@1+ (1,0) [0|0] "" Vector__XXX
 SG_ DAS_eldw m2 : 53|1@1+ (1,0) [0|0] "" Vector__XXX
 SG_ DAS_ACC_Activate_road_class m28 : 54|1@1+ (1,0) [0|0] "" Vector__XXX
 SG_ DAS_ACC_radInFrontOfCIPVRel m20 : 54|1@1+ (1,0) [0|0] "" Vector__XXX
 SG_ DAS_ACC_tgt_cipv2_valid m23 : 54|1@1+ (1,0) [0|0] "" Vector__XXX
 SG_ DAS_ACC_tgt_cipv_valid m22 : 54|1@1+ (1,0) [0|0] "" Vector__XXX
 SG_ DAS_ACC_tgt_cutin_valid m26 : 54|1@1+ (1,0) [0|0] "" Vector__XXX
 SG_ DAS_ACC_tgt_mcvl_valid m24 : 54|1@1+ (1,0) [0|0] "" Vector__XXX
 SG_ DAS_ACC_tgt_mcvr_valid m25 : 54|1@1+ (1,0) [0|0] "" Vector__XXX
 SG_ DAS_FCM_TA_distDiffSteerAeb m33 : 54|8@1+ (0.1,0) [0|0] "" Vector__XXX
 SG_ DAS_TFL_warning m4 : 54|1@1+ (1,0) [0|0] "" Vector__XXX
 SG_ DAS_VL_RL_fuse m51 : 54|1@1+ (1,0) [0|0] "" Vector__XXX
 SG_ DAS_VL_V4_quality m50 : 54|1@1+ (1,0) [0|0] "" Vector__XXX
 SG_ DAS_laneMerge m2 : 54|2@1+ (1,0) [0|0] "" Vector__XXX
 SG_ DAS_ACC_Activate_stw_angle m28 : 55|1@1+ (1,0) [0|0] "" Vector__XXX
 SG_ DAS_ACC_tgt_cipv2_new m23 : 55|1@1+ (1,0) [0|0] "" Vector__XXX
 SG_ DAS_ACC_tgt_cipv_new m22 : 55|1@1+ (1,0) [0|0] "" Vector__XXX
 SG_ DAS_ACC_tgt_cutin_new m26 : 55|1@1+ (1,0) [0|0] "" Vector__XXX
 SG_ DAS_ACC_tgt_mcvl_new m24 : 55|1@1+ (1,0) [0|0] "" Vector__XXX
 SG_ DAS_ACC_tgt_mcvr_new m25 : 55|1@1+ (1,0) [0|0] "" Vector__XXX
 SG_ DAS_VL_HPP_fuse m51 : 55|1@1+ (1,0) [0|0] "" Vector__XXX
 SG_ DAS_VL_V5_quality m50 : 55|1@1+ (1,0) [0|0] "" Vector__XXX
 SG_ DAS_ACC_Activate_rad_tar_5 m28 : 56|1@1+ (1,0) [0|0] "" Vector__XXX
 SG_ DAS_ACC_Target6_valid m27 : 56|1@1+ (1,0) [0|0] "" Vector__XXX
 SG_ DAS_ACC_controlType m20 : 56|3@1+ (1,0) [0|0] "" Vector__XXX
 SG_ DAS_ACC_tgt_cipv2_copied m23 : 56|1@1+ (1,0) [0|0] "" Vector__XXX
 SG_ DAS_ACC_tgt_cipv_copied m22 : 56|1@1+ (1,0) [0|0] "" Vector__XXX
 SG_ DAS_ACC_tgt_cutin_copied m26 : 56|1@1+ (1,0) [0|0] "" Vector__XXX
 SG_ DAS_ACC_tgt_mcvl_copied m24 : 56|1@1+ (1,0) [0|0] "" Vector__XXX
 SG_ DAS_ACC_tgt_mcvr_copied m25 : 56|1@1+ (1,0) [0|0] "" Vector__XXX
 SG_ DAS_FCM_DBG_ass_age m35 : 56|6@1+ (100,0) [0|0] "" Vector__XXX
 SG_ DAS_LCM_required_driver_accel m39 : 56|8@1- (0.1,-6.3) [0|0] "" Vector__XXX
 SG_ DAS_Planner_c3 m46 : 56|8@1+ (2.4e-07,-3e-05) [0|0] "" Vector__XXX
 SG_ DAS_TFL_mainID m4 : 56|8@1+ (1,0) [0|0] "" Vector__XXX
 SG_ DAS_VL_Mode m50 : 56|4@1+ (1,0) [0|0] "" Vector__XXX
 SG_ DAS_VL_NAV_fuse m51 : 56|1@1+ (1,0) [0|0] "" Vector__XXX
 SG_ DAS_VWall_Right_c3 m44 : 56|8@1+ (2.4e-07,-3e-05) [0|0] "" Vector__XXX
 SG_ DAS_appMobileyeStatus m0 : 56|8@1+ (1,0) [0|0] "" Vector__XXX
 SG_ DAS_csa_desiredVelMeas m47 : 56|8@1+ (0.29,15) [0|0] "" Vector__XXX
 SG_ DAS_freespaceLeftNearZ m2 : 56|4@1+ (4,0) [0|0] "" Vector__XXX
 SG_ DAS_unusedW0 m3 : 56|8@1+ (1,0) [0|0] "" Vector__XXX
 SG_ DAS_ACC_Activate_ultra_obs m28 : 57|1@1+ (1,0) [0|0] "" Vector__XXX
 SG_ DAS_ACC_Target6_new m27 : 57|1@1+ (1,0) [0|0] "" Vector__XXX
 SG_ DAS_ACC_tgt_cipv2_brakeLights m23 : 57|1@1+ (1,0) [0|0] "" Vector__XXX
 SG_ DAS_ACC_tgt_cipv_brakeLights m22 : 57|1@1+ (1,0) [0|0] "" Vector__XXX
 SG_ DAS_ACC_tgt_cutin_brakeLights m26 : 57|1@1+ (1,0) [0|0] "" Vector__XXX
 SG_ DAS_ACC_tgt_mcvl_brakeLights m24 : 57|1@1+ (1,0) [0|0] "" Vector__XXX
 SG_ DAS_ACC_tgt_mcvr_brakeLights m25 : 57|1@1+ (1,0) [0|0] "" Vector__XXX
 SG_ DAS_VL_V1_fuse m51 : 57|1@1+ (1,0) [0|0] "" Vector__XXX
 SG_ DAS_hands_on_detected_default m45 : 57|1@1+ (1,0) [0|0] "" Vector__XXX
 SG_ DAS_ACC_Activate_freespace m28 : 58|1@1+ (1,0) [0|0] "" Vector__XXX
 SG_ DAS_ACC_Target6_stop_line_raw m27 : 58|1@1+ (1,0) [0|0] "" Vector__XXX
 SG_ DAS_ACC_tgt_cipv2_blinkerLeft m23 : 58|1@1+ (1,0) [0|0] "" Vector__XXX
 SG_ DAS_ACC_tgt_cipv_blinkerLeft m22 : 58|1@1+ (1,0) [0|0] "" Vector__XXX
 SG_ DAS_ACC_tgt_cutin_blinkerLeft m26 : 58|1@1+ (1,0) [0|0] "" Vector__XXX
 SG_ DAS_ACC_tgt_mcvl_blinkerLeft m24 : 58|1@1+ (1,0) [0|0] "" Vector__XXX
 SG_ DAS_ACC_tgt_mcvr_blinkerLeft m25 : 58|1@1+ (1,0) [0|0] "" Vector__XXX
 SG_ DAS_LCM_CIPV_headway_time m38 : 58|6@1+ (0.1,0) [0|0] "" Vector__XXX
 SG_ DAS_VL_V2_fuse m51 : 58|1@1+ (1,0) [0|0] "" Vector__XXX
 SG_ DAS_hands_on_detected_offset m45 : 58|1@1+ (1,0) [0|0] "" Vector__XXX
 SG_ DAS_ACC_Activate_pedestrian m28 : 59|1@1+ (1,0) [0|0] "" Vector__XXX
 SG_ DAS_ACC_Target6_delay m27 : 59|4@1+ (20,0) [0|0] "" Vector__XXX
 SG_ DAS_ACC_overtakeMode m20 : 59|2@1+ (1,0) [0|0] "" Vector__XXX
 SG_ DAS_ACC_tgt_cipv2_blinkerRight m23 : 59|1@1+ (1,0) [0|0] "" Vector__XXX
 SG_ DAS_ACC_tgt_cipv_blinkerRight m22 : 59|1@1+ (1,0) [0|0] "" Vector__XXX
 SG_ DAS_ACC_tgt_cutin_blinkerRight m26 : 59|1@1+ (1,0) [0|0] "" Vector__XXX
 SG_ DAS_ACC_tgt_mcvl_blinkerRight m24 : 59|1@1+ (1,0) [0|0] "" Vector__XXX
 SG_ DAS_ACC_tgt_mcvr_blinkerRight m25 : 59|1@1+ (1,0) [0|0] "" Vector__XXX
 SG_ DAS_VL_V3_fuse m51 : 59|1@1+ (1,0) [0|0] "" Vector__XXX
 SG_ DAS_hands_on_warning_cipv_valid m45 : 59|1@1+ (1,0) [0|0] "" Vector__XXX
 SG_ DAS_ACC_tgt_cipv2_delay m23 : 60|4@1+ (20,0) [0|0] "" Vector__XXX
 SG_ DAS_ACC_tgt_cipv_delay m22 : 60|4@1+ (20,0) [0|0] "" Vector__XXX
 SG_ DAS_ACC_tgt_cutin_delay m26 : 60|4@1+ (20,0) [0|0] "" Vector__XXX
 SG_ DAS_ACC_tgt_mcvl_delay m24 : 60|4@1+ (20,0) [0|0] "" Vector__XXX
 SG_ DAS_ACC_tgt_mcvr_delay m25 : 60|4@1+ (20,0) [0|0] "" Vector__XXX
 SG_ DAS_LCM_CIPV_type m37 : 60|2@1+ (1,0) [0|0] "" Vector__XXX
 SG_ DAS_SCA_egoMovingRight m45 : 60|1@1+ (1,0) [0|0] "" Vector__XXX
 SG_ DAS_VL_LinePreference m50 : 60|3@1+ (1,0) [0|0] "" Vector__XXX
 SG_ DAS_VL_V4_fuse m51 : 60|1@1+ (1,0) [0|0] "" Vector__XXX
 SG_ DAS_freespaceRightNearZ m2 : 60|4@1+ (4,0) [0|0] "" Vector__XXX
 SG_ DAS_FCM_CIPV_valid m30 : 61|1@1+ (1,0) [0|0] "" Vector__XXX
 SG_ DAS_FCM_MCP_valid m31 : 61|1@1+ (1,0) [0|0] "" Vector__XXX
 SG_ DAS_FCM_SL_valid m32 : 61|1@1+ (1,0) [0|0] "" Vector__XXX
 SG_ DAS_HmVlNoInputsOAL m42 : 61|3@1+ (1,0) [0|0] "" Vector__XXX
 SG_ DAS_SCA_polyValid m45 : 61|1@1+ (1,0) [0|0] "" Vector__XXX
 SG_ DAS_VL_V5_fuse m51 : 61|1@1+ (1,0) [0|0] "" Vector__XXX
 SG_ DAS_accTimeGap m6 : 61|3@1+ (0.2,0.8) [0|0] "" Vector__XXX
 SG_ DAS_pp_laneChange_freesp_avail_l m48 : 61|1@1+ (1,0) [0|0] "" Vector__XXX
 SG_ DAS_ACC_BCW_decelCheck m20 : 62|1@1+ (1,0) [0|0] "" Vector__XXX
 SG_ DAS_FCM_CIPV_radarMatchConfOK m30 : 62|1@1+ (1,0) [0|0] "" Vector__XXX
 SG_ DAS_FCM_MCP_radarMatchConfOK m31 : 62|1@1+ (1,0) [0|0] "" Vector__XXX
 SG_ DAS_FCM_SL_radarMatchConfOK m32 : 62|1@1+ (1,0) [0|0] "" Vector__XXX
 SG_ DAS_FCM_TA_mode m33 : 62|2@1+ (1,0) [0|0] "" Vector__XXX
 SG_ DAS_LCM_CIPV_valid m37 : 62|1@1+ (1,0) [0|0] "" Vector__XXX
 SG_ DAS_SCA_egoCentered m45 : 62|1@1+ (1,0) [0|0] "" Vector__XXX
 SG_ DAS_VL_egoLaneChange m51 : 62|2@1+ (1,0) [0|0] "" Vector__XXX
 SG_ DAS_pp_laneChange_freesp_avail_r m48 : 62|1@1+ (1,0) [0|0] "" Vector__XXX
 SG_ DAS_ACC_BCW m20 : 63|1@1+ (1,0) [0|0] "" Vector__XXX
 SG_ DAS_LC_Hands_On_Caused_By_Curve m40 : 63|1@1+ (1,0) [0|0] "" Vector__XXX
 SG_ DAS_driver_interaction_detected m45 : 63|1@1+ (1,0) [0|0] "" Vector__XXX

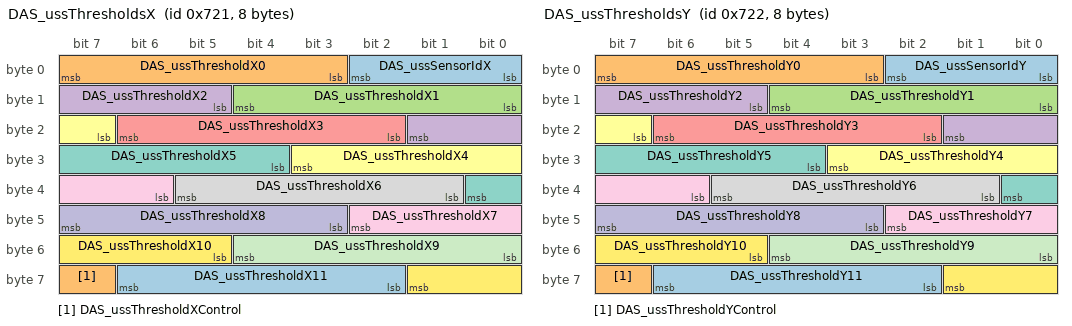
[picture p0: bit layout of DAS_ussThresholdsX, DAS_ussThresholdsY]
BO_ 1825 DAS_ussThresholdsX: 8 Vector__XXX
 SG_ DAS_ussSensorIdX : 0|3@1+ (1,0) [0|0] "" Vector__XXX
 SG_ DAS_ussThresholdX0 : 3|5@1+ (1,0) [0|0] "" Vector__XXX
 SG_ DAS_ussThresholdX1 : 8|5@1+ (1,0) [0|0] "" Vector__XXX
 SG_ DAS_ussThresholdX2 : 13|5@1+ (1,0) [0|0] "" Vector__XXX
 SG_ DAS_ussThresholdX3 : 18|5@1+ (1,0) [0|0] "" Vector__XXX
 SG_ DAS_ussThresholdX4 : 23|5@1+ (1,0) [0|0] "" Vector__XXX
 SG_ DAS_ussThresholdX5 : 28|5@1+ (1,0) [0|0] "" Vector__XXX
 SG_ DAS_ussThresholdX6 : 33|5@1+ (1,0) [0|0] "" Vector__XXX
 SG_ DAS_ussThresholdX7 : 38|5@1+ (1,0) [0|0] "" Vector__XXX
 SG_ DAS_ussThresholdX8 : 43|5@1+ (1,0) [0|0] "" Vector__XXX
 SG_ DAS_ussThresholdX9 : 48|5@1+ (1,0) [0|0] "" Vector__XXX
 SG_ DAS_ussThresholdX10 : 53|5@1+ (1,0) [0|0] "" Vector__XXX
 SG_ DAS_ussThresholdX11 : 58|5@1+ (1,0) [0|0] "" Vector__XXX
 SG_ DAS_ussThresholdXControl : 63|1@1+ (1,0) [0|0] "" Vector__XXX

BO_ 1826 DAS_ussThresholdsY: 8 Vector__XXX
 SG_ DAS_ussSensorIdY : 0|3@1+ (1,0) [0|0] "" Vector__XXX
 SG_ DAS_ussThresholdY0 : 3|5@1+ (1,0) [0|0] "" Vector__XXX
 SG_ DAS_ussThresholdY1 : 8|5@1+ (1,0) [0|0] "" Vector__XXX
 SG_ DAS_ussThresholdY2 : 13|5@1+ (1,0) [0|0] "" Vector__XXX
 SG_ DAS_ussThresholdY3 : 18|5@1+ (1,0) [0|0] "" Vector__XXX
 SG_ DAS_ussThresholdY4 : 23|5@1+ (1,0) [0|0] "" Vector__XXX
 SG_ DAS_ussThresholdY5 : 28|5@1+ (1,0) [0|0] "" Vector__XXX
 SG_ DAS_ussThresholdY6 : 33|5@1+ (1,0) [0|0] "" Vector__XXX
 SG_ DAS_ussThresholdY7 : 38|5@1+ (1,0) [0|0] "" Vector__XXX
 SG_ DAS_ussThresholdY8 : 43|5@1+ (1,0) [0|0] "" Vector__XXX
 SG_ DAS_ussThresholdY9 : 48|5@1+ (1,0) [0|0] "" Vector__XXX
 SG_ DAS_ussThresholdY10 : 53|5@1+ (1,0) [0|0] "" Vector__XXX
 SG_ DAS_ussThresholdY11 : 58|5@1+ (1,0) [0|0] "" Vector__XXX
 SG_ DAS_ussThresholdYControl : 63|1@1+ (1,0) [0|0] "" Vector__XXX

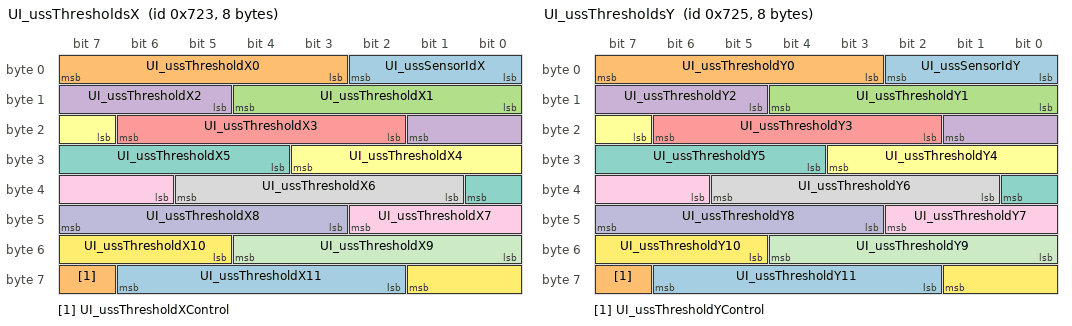
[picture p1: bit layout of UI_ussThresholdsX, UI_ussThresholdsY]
BO_ 1827 UI_ussThresholdsX: 8 Vector__XXX
 SG_ UI_ussSensorIdX : 0|3@1+ (1,0) [0|0] "" Vector__XXX
 SG_ UI_ussThresholdX0 : 3|5@1+ (1,0) [0|0] "" Vector__XXX
 SG_ UI_ussThresholdX1 : 8|5@1+ (1,0) [0|0] "" Vector__XXX
 SG_ UI_ussThresholdX2 : 13|5@1+ (1,0) [0|0] "" Vector__XXX
 SG_ UI_ussThresholdX3 : 18|5@1+ (1,0) [0|0] "" Vector__XXX
 SG_ UI_ussThresholdX4 : 23|5@1+ (1,0) [0|0] "" Vector__XXX
 SG_ UI_ussThresholdX5 : 28|5@1+ (1,0) [0|0] "" Vector__XXX
 SG_ UI_ussThresholdX6 : 33|5@1+ (1,0) [0|0] "" Vector__XXX
 SG_ UI_ussThresholdX7 : 38|5@1+ (1,0) [0|0] "" Vector__XXX
 SG_ UI_ussThresholdX8 : 43|5@1+ (1,0) [0|0] "" Vector__XXX
 SG_ UI_ussThresholdX9 : 48|5@1+ (1,0) [0|0] "" Vector__XXX
 SG_ UI_ussThresholdX10 : 53|5@1+ (1,0) [0|0] "" Vector__XXX
 SG_ UI_ussThresholdX11 : 58|5@1+ (1,0) [0|0] "" Vector__XXX
 SG_ UI_ussThresholdXControl : 63|1@1+ (1,0) [0|0] "" Vector__XXX

BO_ 1829 UI_ussThresholdsY: 8 Vector__XXX
 SG_ UI_ussSensorIdY : 0|3@1+ (1,0) [0|0] "" Vector__XXX
 SG_ UI_ussThresholdY0 : 3|5@1+ (1,0) [0|0] "" Vector__XXX
 SG_ UI_ussThresholdY1 : 8|5@1+ (1,0) [0|0] "" Vector__XXX
 SG_ UI_ussThresholdY2 : 13|5@1+ (1,0) [0|0] "" Vector__XXX
 SG_ UI_ussThresholdY3 : 18|5@1+ (1,0) [0|0] "" Vector__XXX
 SG_ UI_ussThresholdY4 : 23|5@1+ (1,0) [0|0] "" Vector__XXX
 SG_ UI_ussThresholdY5 : 28|5@1+ (1,0) [0|0] "" Vector__XXX
 SG_ UI_ussThresholdY6 : 33|5@1+ (1,0) [0|0] "" Vector__XXX
 SG_ UI_ussThresholdY7 : 38|5@1+ (1,0) [0|0] "" Vector__XXX
 SG_ UI_ussThresholdY8 : 43|5@1+ (1,0) [0|0] "" Vector__XXX
 SG_ UI_ussThresholdY9 : 48|5@1+ (1,0) [0|0] "" Vector__XXX
 SG_ UI_ussThresholdY10 : 53|5@1+ (1,0) [0|0] "" Vector__XXX
 SG_ UI_ussThresholdY11 : 58|5@1+ (1,0) [0|0] "" Vector__XXX
 SG_ UI_ussThresholdYControl : 63|1@1+ (1,0) [0|0] "" Vector__XXX

BO_ 1833 DBG_IsotermSMS: 12 Vector__XXX
 SG_ DBG_IsotermSMS : 7|64@0+ (1,0) [0|0] "" Vector__XXX

BO_ 1835 XCP_tasRequest: 12 Vector__XXX
 SG_ XCP_tasRequest : 7|64@0+ (1,0) [0|0] "" Vector__XXX

BO_ 1840 UDS_epas3sRequest: 12 Vector__XXX
 SG_ UDS_epas3sRequestData : 7|64@0+ (1,0) [0|0] "" Vector__XXX

BO_ 1848 EPAS3S_udsResponse: 12 Vector__XXX
 SG_ EPAS3S_udsResponseData : 7|64@0+ (1,0) [0|0] "" Vector__XXX

BO_ 1849 DAS_IsotermSMS: 12 Vector__XXX
 SG_ DAS_IsotermSMS : 7|64@0+ (1,0) [0|0] "" Vector__XXX

BO_ 1856 TPMS_sensorIDs: 8 Vector__XXX
 SG_ TPMS_sensorIDIndex M : 0|8@1+ (1,0) [0|0] "" Vector__XXX
 SG_ TPMS_sensorIDFL m0 : 32|32@1+ (1,0) [0|0] "" Vector__XXX
 SG_ TPMS_sensorIDFR m2 : 32|32@1+ (1,0) [0|0] "" Vector__XXX
 SG_ TPMS_sensorIDRL m3 : 32|32@1+ (1,0) [0|0] "" Vector__XXX
 SG_ TPMS_sensorIDRR m1 : 32|32@1+ (1,0) [0|0] "" Vector__XXX

BO_ 1880 XCP_usmRequest: 12 Vector__XXX
 SG_ XCP_usmRequestData : 7|64@0+ (1,0) [0|0] "" Vector__XXX

BO_ 1891 USM_xcpResponse: 8 Vector__XXX
 SG_ USM_xcpResponseData : 0|64@1+ (1,0) [0|0] "" Vector__XXX

BO_ 1929 TRCM_debug: 8 Vector__XXX
 SG_ TRCM_debugSelector M : 0|8@1+ (1,0) [0|0] "" Vector__XXX
 SG_ TRCM_FRONT_CENTER_ACCEL_Data m7 : 8|10@1- (1,0) [0|0] "" Vector__XXX
 SG_ TRCM_FRONT_CENTER_ACCEL_X_Data m12 : 8|10@1- (1,0) [0|0] "" Vector__XXX
 SG_ TRCM_FRONT_CENTER_ACCEL_Y_Data m13 : 8|10@1- (1,0) [0|0] "" Vector__XXX
 SG_ TRCM_FRONT_LEFT_ACCEL_Data m3 : 8|10@1- (1,0) [0|0] "" Vector__XXX
 SG_ TRCM_FRONT_LEFT_DOOR_PRESSURE_Data m4 : 8|10@1- (0.4947265625,0) [0|0] "" Vector__XXX
 SG_ TRCM_FRONT_RIGHT_ACCEL_Data m1 : 8|10@1- (1,0) [0|0] "" Vector__XXX
 SG_ TRCM_FRONT_RIGHT_DOOR_PRESSURE_Data m2 : 8|10@1- (0.4947265625,0) [0|0] "" Vector__XXX
 SG_ TRCM_LEFT_B_PILLAR_ACCEL_Data m6 : 8|10@1- (1,0) [0|0] "" Vector__XXX
 SG_ TRCM_LEFT_C_PILLAR_ACCEL_Data m8 : 8|10@1- (1,0) [0|0] "" Vector__XXX
 SG_ TRCM_REAR_LEFT_DOOR_PRESSURE_Data m11 : 8|10@1- (0.4947265625,0) [0|0] "" Vector__XXX
 SG_ TRCM_REAR_RIGHT_DOOR_PRESSURE_Data m10 : 8|10@1- (0.4947265625,0) [0|0] "" Vector__XXX
 SG_ TRCM_RIGHT_B_PILLAR_ACCEL_Data m5 : 8|10@1- (1,0) [0|0] "" Vector__XXX
 SG_ TRCM_RIGHT_C_PILLAR_ACCEL_Data m9 : 8|10@1- (1,0) [0|0] "" Vector__XXX
 SG_ TRCM_airbagAsicsDiagnosticState m0 : 8|6@1+ (1,0) [0|0] "" Vector__XXX
 SG_ TRCM_boardTemp m20 : 8|8@1+ (1,-40) [0|0] "" Vector__XXX
 SG_ TRCM_deploymentLoopResistance0 m14 : 8|8@1+ (0.05,0) [0|0] "" Vector__XXX
 SG_ TRCM_deploymentLoopResistance14 m16 : 8|8@1+ (0.05,0) [0|0] "" Vector__XXX
 SG_ TRCM_deploymentLoopResistance21 m17 : 8|8@1+ (0.05,0) [0|0] "" Vector__XXX
 SG_ TRCM_deploymentLoopResistance28 m18 : 8|8@1+ (0.05,0) [0|0] "" Vector__XXX
 SG_ TRCM_deploymentLoopResistance7 m15 : 8|8@1+ (0.05,0) [0|0] "" Vector__XXX
 SG_ TRCM_ecuLogUploadState1 m19 : 8|2@1+ (1,0) [0|0] "" Vector__XXX
 SG_ TRCM_ecuLogUploadState8 m23 : 8|2@1+ (1,0) [0|0] "" Vector__XXX
 SG_ TRCM_rcmNotArmed m22 : 8|1@1+ (1,0) [0|0] "" Vector__XXX
 SG_ TRCM_totalCpuLoad m21 : 8|20@1+ (0.0001,0) [0|0] "" Vector__XXX
 SG_ TRCM_rcmForceArmed m22 : 9|1@1+ (1,0) [0|0] "" Vector__XXX
 SG_ TRCM_ecuLogUploadState2 m19 : 10|2@1+ (1,0) [0|0] "" Vector__XXX
 SG_ TRCM_ecuLogUploadState9 m23 : 10|2@1+ (1,0) [0|0] "" Vector__XXX
 SG_ TRCM_sysUnableToDeploy m22 : 10|1@1+ (1,0) [0|0] "" Vector__XXX
 SG_ TRCM_sysSelfTestTimeoutExpired m22 : 11|1@1+ (1,0) [0|0] "" Vector__XXX
 SG_ TRCM_asicGspiNotOkay m22 : 12|1@1+ (1,0) [0|0] "" Vector__XXX
 SG_ TRCM_ecuLogUploadState10 m23 : 12|2@1+ (1,0) [0|0] "" Vector__XXX
 SG_ TRCM_ecuLogUploadState3 m19 : 12|2@1+ (1,0) [0|0] "" Vector__XXX
 SG_ TRCM_asicSafingEnablementNotOkay m22 : 13|1@1+ (1,0) [0|0] "" Vector__XXX
 SG_ TRCM_asicStartupTestsNotOkay m22 : 14|1@1+ (1,0) [0|0] "" Vector__XXX
 SG_ TRCM_ecuLogUploadState11 m23 : 14|2@1+ (1,0) [0|0] "" Vector__XXX
 SG_ TRCM_ecuLogUploadState4 m19 : 14|2@1+ (1,0) [0|0] "" Vector__XXX
 SG_ TRCM_deploymentLoopsNotOkay m22 : 15|1@1+ (1,0) [0|0] "" Vector__XXX
 SG_ TRCM_airbagAsicsFaultReason m0 : 16|6@1+ (1,0) [0|0] "" Vector__XXX
 SG_ TRCM_deploymentLoopResistance1 m14 : 16|8@1+ (0.05,0) [0|0] "" Vector__XXX
 SG_ TRCM_deploymentLoopResistance15 m16 : 16|8@1+ (0.05,0) [0|0] "" Vector__XXX
 SG_ TRCM_deploymentLoopResistance22 m17 : 16|8@1+ (0.05,0) [0|0] "" Vector__XXX
 SG_ TRCM_deploymentLoopResistance29 m18 : 16|8@1+ (0.05,0) [0|0] "" Vector__XXX
 SG_ TRCM_deploymentLoopResistance8 m15 : 16|8@1+ (0.05,0) [0|0] "" Vector__XXX
 SG_ TRCM_ecuLogUploadState5 m19 : 16|2@1+ (1,0) [0|0] "" Vector__XXX
 SG_ TRCM_erCapChargeNotOkay m22 : 16|1@1+ (1,0) [0|0] "" Vector__XXX
 SG_ TRCM_scroll0State m23 : 16|2@1+ (1,0) [0|0] "" Vector__XXX
 SG_ TRCM_systemAsicTemp m20 : 16|8@1+ (1,-40) [0|0] "" Vector__XXX
 SG_ TRCM_erCapDiagnosticsNotOkay m22 : 17|1@1+ (1,0) [0|0] "" Vector__XXX
 SG_ TRCM_FRONT_CENTER_ACCEL_StatusOkay m7 : 18|1@1+ (1,0) [0|0] "" Vector__XXX
 SG_ TRCM_FRONT_CENTER_ACCEL_X_StatusOkay m12 : 18|1@1+ (1,0) [0|0] "" Vector__XXX
 SG_ TRCM_FRONT_CENTER_ACCEL_Y_StatusOkay m13 : 18|1@1+ (1,0) [0|0] "" Vector__XXX
 SG_ TRCM_FRONT_LEFT_ACCEL_StatusOkay m3 : 18|1@1+ (1,0) [0|0] "" Vector__XXX
 SG_ TRCM_FRONT_LEFT_DOOR_PRESSURE_StatusOkay m4 : 18|1@1+ (1,0) [0|0] "" Vector__XXX
 SG_ TRCM_FRONT_RIGHT_ACCEL_StatusOkay m1 : 18|1@1+ (1,0) [0|0] "" Vector__XXX
 SG_ TRCM_FRONT_RIGHT_DOOR_PRESSURE_StatusOkay m2 : 18|1@1+ (1,0) [0|0] "" Vector__XXX
 SG_ TRCM_LEFT_B_PILLAR_ACCEL_StatusOkay m6 : 18|1@1+ (1,0) [0|0] "" Vector__XXX
 SG_ TRCM_LEFT_C_PILLAR_ACCEL_StatusOkay m8 : 18|1@1+ (1,0) [0|0] "" Vector__XXX
 SG_ TRCM_REAR_LEFT_DOOR_PRESSURE_StatusOkay m11 : 18|1@1+ (1,0) [0|0] "" Vector__XXX
 SG_ TRCM_REAR_RIGHT_DOOR_PRESSURE_StatusOkay m10 : 18|1@1+ (1,0) [0|0] "" Vector__XXX
 SG_ TRCM_RIGHT_B_PILLAR_ACCEL_StatusOkay m5 : 18|1@1+ (1,0) [0|0] "" Vector__XXX
 SG_ TRCM_RIGHT_C_PILLAR_ACCEL_StatusOkay m9 : 18|1@1+ (1,0) [0|0] "" Vector__XXX
 SG_ TRCM_asicRsspiNotOkay m22 : 18|1@1+ (1,0) [0|0] "" Vector__XXX
 SG_ TRCM_ecuLogUploadState6 m19 : 18|2@1+ (1,0) [0|0] "" Vector__XXX
 SG_ TRCM_scroll1State m23 : 18|2@1+ (1,0) [0|0] "" Vector__XXX
 SG_ TRCM_FRONT_CENTER_ACCEL_CrcOkay m7 : 19|1@1+ (1,0) [0|0] "" Vector__XXX
 SG_ TRCM_FRONT_CENTER_ACCEL_X_CrcOkay m12 : 19|1@1+ (1,0) [0|0] "" Vector__XXX
 SG_ TRCM_FRONT_CENTER_ACCEL_Y_CrcOkay m13 : 19|1@1+ (1,0) [0|0] "" Vector__XXX
 SG_ TRCM_FRONT_LEFT_ACCEL_CrcOkay m3 : 19|1@1+ (1,0) [0|0] "" Vector__XXX
 SG_ TRCM_FRONT_LEFT_DOOR_PRESSURE_CrcOkay m4 : 19|1@1+ (1,0) [0|0] "" Vector__XXX
 SG_ TRCM_FRONT_RIGHT_ACCEL_CrcOkay m1 : 19|1@1+ (1,0) [0|0] "" Vector__XXX
 SG_ TRCM_FRONT_RIGHT_DOOR_PRESSURE_CrcOkay m2 : 19|1@1+ (1,0) [0|0] "" Vector__XXX
 SG_ TRCM_LEFT_B_PILLAR_ACCEL_CrcOkay m6 : 19|1@1+ (1,0) [0|0] "" Vector__XXX
 SG_ TRCM_LEFT_C_PILLAR_ACCEL_CrcOkay m8 : 19|1@1+ (1,0) [0|0] "" Vector__XXX
 SG_ TRCM_REAR_LEFT_DOOR_PRESSURE_CrcOkay m11 : 19|1@1+ (1,0) [0|0] "" Vector__XXX
 SG_ TRCM_REAR_RIGHT_DOOR_PRESSURE_CrcOkay m10 : 19|1@1+ (1,0) [0|0] "" Vector__XXX
 SG_ TRCM_RIGHT_B_PILLAR_ACCEL_CrcOkay m5 : 19|1@1+ (1,0) [0|0] "" Vector__XXX
 SG_ TRCM_RIGHT_C_PILLAR_ACCEL_CrcOkay m9 : 19|1@1+ (1,0) [0|0] "" Vector__XXX
 SG_ TRCM_mcuHwDiagnosticNotOkay m22 : 19|1@1+ (1,0) [0|0] "" Vector__XXX
 SG_ TRCM_FRONT_CENTER_ACCEL_FrameCounterOkay m7 : 20|1@1+ (1,0) [0|0] "" Vector__XXX
 SG_ TRCM_FRONT_CENTER_ACCEL_X_FrameCounterOkay m12 : 20|1@1+ (1,0) [0|0] "" Vector__XXX
 SG_ TRCM_FRONT_CENTER_ACCEL_Y_FrameCounterOkay m13 : 20|1@1+ (1,0) [0|0] "" Vector__XXX
 SG_ TRCM_FRONT_LEFT_ACCEL_FrameCounterOkay m3 : 20|1@1+ (1,0) [0|0] "" Vector__XXX
 SG_ TRCM_FRONT_LEFT_DOOR_PRESSURE_FrameCounterOkay m4 : 20|1@1+ (1,0) [0|0] "" Vector__XXX
 SG_ TRCM_FRONT_RIGHT_ACCEL_FrameCounterOkay m1 : 20|1@1+ (1,0) [0|0] "" Vector__XXX
 SG_ TRCM_FRONT_RIGHT_DOOR_PRESSURE_FrameCounterOkay m2 : 20|1@1+ (1,0) [0|0] "" Vector__XXX
 SG_ TRCM_LEFT_B_PILLAR_ACCEL_FrameCounterOkay m6 : 20|1@1+ (1,0) [0|0] "" Vector__XXX
 SG_ TRCM_LEFT_C_PILLAR_ACCEL_FrameCounterOkay m8 : 20|1@1+ (1,0) [0|0] "" Vector__XXX
 SG_ TRCM_REAR_LEFT_DOOR_PRESSURE_FrameCounterOkay m11 : 20|1@1+ (1,0) [0|0] "" Vector__XXX
 SG_ TRCM_REAR_RIGHT_DOOR_PRESSURE_FrameCounterOkay m10 : 20|1@1+ (1,0) [0|0] "" Vector__XXX
 SG_ TRCM_RIGHT_B_PILLAR_ACCEL_FrameCounterOkay m5 : 20|1@1+ (1,0) [0|0] "" Vector__XXX
 SG_ TRCM_RIGHT_C_PILLAR_ACCEL_FrameCounterOkay m9 : 20|1@1+ (1,0) [0|0] "" Vector__XXX
 SG_ TRCM_ecuLogUploadState7 m19 : 20|2@1+ (1,0) [0|0] "" Vector__XXX
 SG_ TRCM_safingMonitorNotOkay m22 : 20|1@1+ (1,0) [0|0] "" Vector__XXX
 SG_ TRCM_scrollReportState m23 : 20|4@1+ (1,0) [0|0] "" Vector__XXX
 SG_ TRCM_FRONT_CENTER_ACCEL_LcidOkay m7 : 21|1@1+ (1,0) [0|0] "" Vector__XXX
 SG_ TRCM_FRONT_CENTER_ACCEL_X_LcidOkay m12 : 21|1@1+ (1,0) [0|0] "" Vector__XXX
 SG_ TRCM_FRONT_CENTER_ACCEL_Y_LcidOkay m13 : 21|1@1+ (1,0) [0|0] "" Vector__XXX
 SG_ TRCM_FRONT_LEFT_ACCEL_LcidOkay m3 : 21|1@1+ (1,0) [0|0] "" Vector__XXX
 SG_ TRCM_FRONT_LEFT_DOOR_PRESSURE_LcidOkay m4 : 21|1@1+ (1,0) [0|0] "" Vector__XXX
 SG_ TRCM_FRONT_RIGHT_ACCEL_LcidOkay m1 : 21|1@1+ (1,0) [0|0] "" Vector__XXX
 SG_ TRCM_FRONT_RIGHT_DOOR_PRESSURE_LcidOkay m2 : 21|1@1+ (1,0) [0|0] "" Vector__XXX
 SG_ TRCM_LEFT_B_PILLAR_ACCEL_LcidOkay m6 : 21|1@1+ (1,0) [0|0] "" Vector__XXX
 SG_ TRCM_LEFT_C_PILLAR_ACCEL_LcidOkay m8 : 21|1@1+ (1,0) [0|0] "" Vector__XXX
 SG_ TRCM_REAR_LEFT_DOOR_PRESSURE_LcidOkay m11 : 21|1@1+ (1,0) [0|0] "" Vector__XXX
 SG_ TRCM_REAR_RIGHT_DOOR_PRESSURE_LcidOkay m10 : 21|1@1+ (1,0) [0|0] "" Vector__XXX
 SG_ TRCM_RIGHT_B_PILLAR_ACCEL_LcidOkay m5 : 21|1@1+ (1,0) [0|0] "" Vector__XXX
 SG_ TRCM_RIGHT_C_PILLAR_ACCEL_LcidOkay m9 : 21|1@1+ (1,0) [0|0] "" Vector__XXX
 SG_ TRCM_buckleStatusFrontLeftNotOkay m22 : 21|1@1+ (1,0) [0|0] "" Vector__XXX
 SG_ TRCM_FRONT_CENTER_ACCEL_NODATA m7 : 22|1@1+ (1,0) [0|0] "" Vector__XXX
 SG_ TRCM_FRONT_CENTER_ACCEL_X_NODATA m12 : 22|1@1+ (1,0) [0|0] "" Vector__XXX
 SG_ TRCM_FRONT_CENTER_ACCEL_Y_NODATA m13 : 22|1@1+ (1,0) [0|0] "" Vector__XXX
 SG_ TRCM_FRONT_LEFT_ACCEL_NODATA m3 : 22|1@1+ (1,0) [0|0] "" Vector__XXX
 SG_ TRCM_FRONT_LEFT_DOOR_PRESSURE_NODATA m4 : 22|1@1+ (1,0) [0|0] "" Vector__XXX
 SG_ TRCM_FRONT_RIGHT_ACCEL_NODATA m1 : 22|1@1+ (1,0) [0|0] "" Vector__XXX
 SG_ TRCM_FRONT_RIGHT_DOOR_PRESSURE_NODATA m2 : 22|1@1+ (1,0) [0|0] "" Vector__XXX
 SG_ TRCM_Hercules0State m19 : 22|2@1+ (1,0) [0|0] "" Vector__XXX
 SG_ TRCM_LEFT_B_PILLAR_ACCEL_NODATA m6 : 22|1@1+ (1,0) [0|0] "" Vector__XXX
 SG_ TRCM_LEFT_C_PILLAR_ACCEL_NODATA m8 : 22|1@1+ (1,0) [0|0] "" Vector__XXX
 SG_ TRCM_REAR_LEFT_DOOR_PRESSURE_NODATA m11 : 22|1@1+ (1,0) [0|0] "" Vector__XXX
 SG_ TRCM_REAR_RIGHT_DOOR_PRESSURE_NODATA m10 : 22|1@1+ (1,0) [0|0] "" Vector__XXX
 SG_ TRCM_RIGHT_B_PILLAR_ACCEL_NODATA m5 : 22|1@1+ (1,0) [0|0] "" Vector__XXX
 SG_ TRCM_RIGHT_C_PILLAR_ACCEL_NODATA m9 : 22|1@1+ (1,0) [0|0] "" Vector__XXX
 SG_ TRCM_buckleStatusFrontRightNotOkay m22 : 22|1@1+ (1,0) [0|0] "" Vector__XXX
 SG_ TRCM_FRONT_CENTER_ACCEL_SLOT m7 : 23|1@1+ (1,0) [0|0] "" Vector__XXX
 SG_ TRCM_FRONT_CENTER_ACCEL_X_SLOT m12 : 23|1@1+ (1,0) [0|0] "" Vector__XXX
 SG_ TRCM_FRONT_CENTER_ACCEL_Y_SLOT m13 : 23|1@1+ (1,0) [0|0] "" Vector__XXX
 SG_ TRCM_FRONT_LEFT_ACCEL_SLOT m3 : 23|1@1+ (1,0) [0|0] "" Vector__XXX
 SG_ TRCM_FRONT_LEFT_DOOR_PRESSURE_SLOT m4 : 23|1@1+ (1,0) [0|0] "" Vector__XXX
 SG_ TRCM_FRONT_RIGHT_ACCEL_SLOT m1 : 23|1@1+ (1,0) [0|0] "" Vector__XXX
 SG_ TRCM_FRONT_RIGHT_DOOR_PRESSURE_SLOT m2 : 23|1@1+ (1,0) [0|0] "" Vector__XXX
 SG_ TRCM_LEFT_B_PILLAR_ACCEL_SLOT m6 : 23|1@1+ (1,0) [0|0] "" Vector__XXX
 SG_ TRCM_LEFT_C_PILLAR_ACCEL_SLOT m8 : 23|1@1+ (1,0) [0|0] "" Vector__XXX
 SG_ TRCM_REAR_LEFT_DOOR_PRESSURE_SLOT m11 : 23|1@1+ (1,0) [0|0] "" Vector__XXX
 SG_ TRCM_REAR_RIGHT_DOOR_PRESSURE_SLOT m10 : 23|1@1+ (1,0) [0|0] "" Vector__XXX
 SG_ TRCM_RIGHT_B_PILLAR_ACCEL_SLOT m5 : 23|1@1+ (1,0) [0|0] "" Vector__XXX
 SG_ TRCM_RIGHT_C_PILLAR_ACCEL_SLOT m9 : 23|1@1+ (1,0) [0|0] "" Vector__XXX
 SG_ TRCM_buckleStatusRearLeftNotOkay m22 : 23|1@1+ (1,0) [0|0] "" Vector__XXX
 SG_ TRCM_FRONT_CENTER_ACCEL_INVALID m7 : 24|1@1+ (1,0) [0|0] "" Vector__XXX
 SG_ TRCM_FRONT_CENTER_ACCEL_X_INVALID m12 : 24|1@1+ (1,0) [0|0] "" Vector__XXX
 SG_ TRCM_FRONT_CENTER_ACCEL_Y_INVALID m13 : 24|1@1+ (1,0) [0|0] "" Vector__XXX
 SG_ TRCM_FRONT_LEFT_ACCEL_INVALID m3 : 24|1@1+ (1,0) [0|0] "" Vector__XXX
 SG_ TRCM_FRONT_LEFT_DOOR_PRESSURE_INVALID m4 : 24|1@1+ (1,0) [0|0] "" Vector__XXX
 SG_ TRCM_FRONT_RIGHT_ACCEL_INVALID m1 : 24|1@1+ (1,0) [0|0] "" Vector__XXX
 SG_ TRCM_FRONT_RIGHT_DOOR_PRESSURE_INVALID m2 : 24|1@1+ (1,0) [0|0] "" Vector__XXX
 SG_ TRCM_Hercules1State m19 : 24|2@1+ (1,0) [0|0] "" Vector__XXX
 SG_ TRCM_LEFT_B_PILLAR_ACCEL_INVALID m6 : 24|1@1+ (1,0) [0|0] "" Vector__XXX
 SG_ TRCM_LEFT_C_PILLAR_ACCEL_INVALID m8 : 24|1@1+ (1,0) [0|0] "" Vector__XXX
 SG_ TRCM_REAR_LEFT_DOOR_PRESSURE_INVALID m11 : 24|1@1+ (1,0) [0|0] "" Vector__XXX
 SG_ TRCM_REAR_RIGHT_DOOR_PRESSURE_INVALID m10 : 24|1@1+ (1,0) [0|0] "" Vector__XXX
 SG_ TRCM_RIGHT_B_PILLAR_ACCEL_INVALID m5 : 24|1@1+ (1,0) [0|0] "" Vector__XXX
 SG_ TRCM_RIGHT_C_PILLAR_ACCEL_INVALID m9 : 24|1@1+ (1,0) [0|0] "" Vector__XXX
 SG_ TRCM_buckleStatusRearRightNotOkay m22 : 24|1@1+ (1,0) [0|0] "" Vector__XXX
 SG_ TRCM_deploymentLoopResistance16 m16 : 24|8@1+ (0.05,0) [0|0] "" Vector__XXX
 SG_ TRCM_deploymentLoopResistance2 m14 : 24|8@1+ (0.05,0) [0|0] "" Vector__XXX
 SG_ TRCM_deploymentLoopResistance23 m17 : 24|8@1+ (0.05,0) [0|0] "" Vector__XXX
 SG_ TRCM_deploymentLoopResistance30 m18 : 24|8@1+ (0.05,0) [0|0] "" Vector__XXX
 SG_ TRCM_deploymentLoopResistance9 m15 : 24|8@1+ (0.05,0) [0|0] "" Vector__XXX
 SG_ TRCM_extenderAsic1Temp m20 : 24|8@1+ (1,-40) [0|0] "" Vector__XXX
 SG_ TRCM_glacierState m0 : 24|5@1+ (1,0) [0|0] "" Vector__XXX
 SG_ TRCM_scrollLogNumber m23 : 24|4@1+ (1,0) [0|0] "" Vector__XXX
 SG_ TRCM_FRONT_CENTER_ACCEL_OPEN m7 : 25|1@1+ (1,0) [0|0] "" Vector__XXX
 SG_ TRCM_FRONT_CENTER_ACCEL_X_OPEN m12 : 25|1@1+ (1,0) [0|0] "" Vector__XXX
 SG_ TRCM_FRONT_CENTER_ACCEL_Y_OPEN m13 : 25|1@1+ (1,0) [0|0] "" Vector__XXX
 SG_ TRCM_FRONT_LEFT_ACCEL_OPEN m3 : 25|1@1+ (1,0) [0|0] "" Vector__XXX
 SG_ TRCM_FRONT_LEFT_DOOR_PRESSURE_OPEN m4 : 25|1@1+ (1,0) [0|0] "" Vector__XXX
 SG_ TRCM_FRONT_RIGHT_ACCEL_OPEN m1 : 25|1@1+ (1,0) [0|0] "" Vector__XXX
 SG_ TRCM_FRONT_RIGHT_DOOR_PRESSURE_OPEN m2 : 25|1@1+ (1,0) [0|0] "" Vector__XXX
 SG_ TRCM_LEFT_B_PILLAR_ACCEL_OPEN m6 : 25|1@1+ (1,0) [0|0] "" Vector__XXX
 SG_ TRCM_LEFT_C_PILLAR_ACCEL_OPEN m8 : 25|1@1+ (1,0) [0|0] "" Vector__XXX
 SG_ TRCM_REAR_LEFT_DOOR_PRESSURE_OPEN m11 : 25|1@1+ (1,0) [0|0] "" Vector__XXX
 SG_ TRCM_REAR_RIGHT_DOOR_PRESSURE_OPEN m10 : 25|1@1+ (1,0) [0|0] "" Vector__XXX
 SG_ TRCM_RIGHT_B_PILLAR_ACCEL_OPEN m5 : 25|1@1+ (1,0) [0|0] "" Vector__XXX
 SG_ TRCM_RIGHT_C_PILLAR_ACCEL_OPEN m9 : 25|1@1+ (1,0) [0|0] "" Vector__XXX
 SG_ TRCM_ocsNotOkay m22 : 25|1@1+ (1,0) [0|0] "" Vector__XXX
 SG_ TRCM_FRONT_CENTER_ACCEL_CURRENT_HI m7 : 26|1@1+ (1,0) [0|0] "" Vector__XXX
 SG_ TRCM_FRONT_CENTER_ACCEL_X_CURRENT_HI m12 : 26|1@1+ (1,0) [0|0] "" Vector__XXX
 SG_ TRCM_FRONT_CENTER_ACCEL_Y_CURRENT_HI m13 : 26|1@1+ (1,0) [0|0] "" Vector__XXX
 SG_ TRCM_FRONT_LEFT_ACCEL_CURRENT_HI m3 : 26|1@1+ (1,0) [0|0] "" Vector__XXX
 SG_ TRCM_FRONT_LEFT_DOOR_PRESSURE_CURRENT_HI m4 : 26|1@1+ (1,0) [0|0] "" Vector__XXX
 SG_ TRCM_FRONT_RIGHT_ACCEL_CURRENT_HI m1 : 26|1@1+ (1,0) [0|0] "" Vector__XXX
 SG_ TRCM_FRONT_RIGHT_DOOR_PRESSURE_CURRENT_HI m2 : 26|1@1+ (1,0) [0|0] "" Vector__XXX
 SG_ TRCM_HerculesReportState m19 : 26|4@1+ (1,0) [0|0] "" Vector__XXX
 SG_ TRCM_LEFT_B_PILLAR_ACCEL_CURRENT_HI m6 : 26|1@1+ (1,0) [0|0] "" Vector__XXX
 SG_ TRCM_LEFT_C_PILLAR_ACCEL_CURRENT_HI m8 : 26|1@1+ (1,0) [0|0] "" Vector__XXX
 SG_ TRCM_REAR_LEFT_DOOR_PRESSURE_CURRENT_HI m11 : 26|1@1+ (1,0) [0|0] "" Vector__XXX
 SG_ TRCM_REAR_RIGHT_DOOR_PRESSURE_CURRENT_HI m10 : 26|1@1+ (1,0) [0|0] "" Vector__XXX
 SG_ TRCM_RIGHT_B_PILLAR_ACCEL_CURRENT_HI m5 : 26|1@1+ (1,0) [0|0] "" Vector__XXX
 SG_ TRCM_RIGHT_C_PILLAR_ACCEL_CURRENT_HI m9 : 26|1@1+ (1,0) [0|0] "" Vector__XXX
 SG_ TRCM_seatTrackPosLeftNotOkay m22 : 26|1@1+ (1,0) [0|0] "" Vector__XXX
 SG_ TRCM_FRONT_CENTER_ACCEL_STB m7 : 27|1@1+ (1,0) [0|0] "" Vector__XXX
 SG_ TRCM_FRONT_CENTER_ACCEL_X_STB m12 : 27|1@1+ (1,0) [0|0] "" Vector__XXX
 SG_ TRCM_FRONT_CENTER_ACCEL_Y_STB m13 : 27|1@1+ (1,0) [0|0] "" Vector__XXX
 SG_ TRCM_FRONT_LEFT_ACCEL_STB m3 : 27|1@1+ (1,0) [0|0] "" Vector__XXX
 SG_ TRCM_FRONT_LEFT_DOOR_PRESSURE_STB m4 : 27|1@1+ (1,0) [0|0] "" Vector__XXX
 SG_ TRCM_FRONT_RIGHT_ACCEL_STB m1 : 27|1@1+ (1,0) [0|0] "" Vector__XXX
 SG_ TRCM_FRONT_RIGHT_DOOR_PRESSURE_STB m2 : 27|1@1+ (1,0) [0|0] "" Vector__XXX
 SG_ TRCM_LEFT_B_PILLAR_ACCEL_STB m6 : 27|1@1+ (1,0) [0|0] "" Vector__XXX
 SG_ TRCM_LEFT_C_PILLAR_ACCEL_STB m8 : 27|1@1+ (1,0) [0|0] "" Vector__XXX
 SG_ TRCM_REAR_LEFT_DOOR_PRESSURE_STB m11 : 27|1@1+ (1,0) [0|0] "" Vector__XXX
 SG_ TRCM_REAR_RIGHT_DOOR_PRESSURE_STB m10 : 27|1@1+ (1,0) [0|0] "" Vector__XXX
 SG_ TRCM_RIGHT_B_PILLAR_ACCEL_STB m5 : 27|1@1+ (1,0) [0|0] "" Vector__XXX
 SG_ TRCM_RIGHT_C_PILLAR_ACCEL_STB m9 : 27|1@1+ (1,0) [0|0] "" Vector__XXX
 SG_ TRCM_seatTrackPosRightNotOkay m22 : 27|1@1+ (1,0) [0|0] "" Vector__XXX
 SG_ TRCM_FRONT_CENTER_ACCEL_SYNC_INH m7 : 28|1@1+ (1,0) [0|0] "" Vector__XXX
 SG_ TRCM_FRONT_CENTER_ACCEL_X_SYNC_INH m12 : 28|1@1+ (1,0) [0|0] "" Vector__XXX
 SG_ TRCM_FRONT_CENTER_ACCEL_Y_SYNC_INH m13 : 28|1@1+ (1,0) [0|0] "" Vector__XXX
 SG_ TRCM_FRONT_LEFT_ACCEL_SYNC_INH m3 : 28|1@1+ (1,0) [0|0] "" Vector__XXX
 SG_ TRCM_FRONT_LEFT_DOOR_PRESSURE_SYNC_INH m4 : 28|1@1+ (1,0) [0|0] "" Vector__XXX
 SG_ TRCM_FRONT_RIGHT_ACCEL_SYNC_INH m1 : 28|1@1+ (1,0) [0|0] "" Vector__XXX
 SG_ TRCM_FRONT_RIGHT_DOOR_PRESSURE_SYNC_INH m2 : 28|1@1+ (1,0) [0|0] "" Vector__XXX
 SG_ TRCM_LEFT_B_PILLAR_ACCEL_SYNC_INH m6 : 28|1@1+ (1,0) [0|0] "" Vector__XXX
 SG_ TRCM_LEFT_C_PILLAR_ACCEL_SYNC_INH m8 : 28|1@1+ (1,0) [0|0] "" Vector__XXX
 SG_ TRCM_REAR_LEFT_DOOR_PRESSURE_SYNC_INH m11 : 28|1@1+ (1,0) [0|0] "" Vector__XXX
 SG_ TRCM_REAR_RIGHT_DOOR_PRESSURE_SYNC_INH m10 : 28|1@1+ (1,0) [0|0] "" Vector__XXX
 SG_ TRCM_RIGHT_B_PILLAR_ACCEL_SYNC_INH m5 : 28|1@1+ (1,0) [0|0] "" Vector__XXX
 SG_ TRCM_RIGHT_C_PILLAR_ACCEL_SYNC_INH m9 : 28|1@1+ (1,0) [0|0] "" Vector__XXX
 SG_ TRCM_onboardAccelXLowRangeNotOkay m22 : 28|1@1+ (1,0) [0|0] "" Vector__XXX
 SG_ TRCM_scrollLogState m23 : 28|3@1+ (1,0) [0|0] "" Vector__XXX
 SG_ TRCM_systemState m21 : 28|3@1+ (1,0) [0|0] "" Vector__XXX
 SG_ TRCM_FRONT_CENTER_ACCEL_STG m7 : 29|1@1+ (1,0) [0|0] "" Vector__XXX
 SG_ TRCM_FRONT_CENTER_ACCEL_X_STG m12 : 29|1@1+ (1,0) [0|0] "" Vector__XXX
 SG_ TRCM_FRONT_CENTER_ACCEL_Y_STG m13 : 29|1@1+ (1,0) [0|0] "" Vector__XXX
 SG_ TRCM_FRONT_LEFT_ACCEL_STG m3 : 29|1@1+ (1,0) [0|0] "" Vector__XXX
 SG_ TRCM_FRONT_LEFT_DOOR_PRESSURE_STG m4 : 29|1@1+ (1,0) [0|0] "" Vector__XXX
 SG_ TRCM_FRONT_RIGHT_ACCEL_STG m1 : 29|1@1+ (1,0) [0|0] "" Vector__XXX
 SG_ TRCM_FRONT_RIGHT_DOOR_PRESSURE_STG m2 : 29|1@1+ (1,0) [0|0] "" Vector__XXX
 SG_ TRCM_LEFT_B_PILLAR_ACCEL_STG m6 : 29|1@1+ (1,0) [0|0] "" Vector__XXX
 SG_ TRCM_LEFT_C_PILLAR_ACCEL_STG m8 : 29|1@1+ (1,0) [0|0] "" Vector__XXX
 SG_ TRCM_REAR_LEFT_DOOR_PRESSURE_STG m11 : 29|1@1+ (1,0) [0|0] "" Vector__XXX
 SG_ TRCM_REAR_RIGHT_DOOR_PRESSURE_STG m10 : 29|1@1+ (1,0) [0|0] "" Vector__XXX
 SG_ TRCM_RIGHT_B_PILLAR_ACCEL_STG m5 : 29|1@1+ (1,0) [0|0] "" Vector__XXX
 SG_ TRCM_RIGHT_C_PILLAR_ACCEL_STG m9 : 29|1@1+ (1,0) [0|0] "" Vector__XXX
 SG_ TRCM_onboardAccelYLowRangeNotOkay m22 : 29|1@1+ (1,0) [0|0] "" Vector__XXX
 SG_ TRCM_FRONT_CENTER_ACCEL_RSTEMP m7 : 30|1@1+ (1,0) [0|0] "" Vector__XXX
 SG_ TRCM_FRONT_CENTER_ACCEL_X_RSTEMP m12 : 30|1@1+ (1,0) [0|0] "" Vector__XXX
 SG_ TRCM_FRONT_CENTER_ACCEL_Y_RSTEMP m13 : 30|1@1+ (1,0) [0|0] "" Vector__XXX
 SG_ TRCM_FRONT_LEFT_ACCEL_RSTEMP m3 : 30|1@1+ (1,0) [0|0] "" Vector__XXX
 SG_ TRCM_FRONT_LEFT_DOOR_PRESSURE_RSTEMP m4 : 30|1@1+ (1,0) [0|0] "" Vector__XXX
 SG_ TRCM_FRONT_RIGHT_ACCEL_RSTEMP m1 : 30|1@1+ (1,0) [0|0] "" Vector__XXX
 SG_ TRCM_FRONT_RIGHT_DOOR_PRESSURE_RSTEMP m2 : 30|1@1+ (1,0) [0|0] "" Vector__XXX
 SG_ TRCM_LEFT_B_PILLAR_ACCEL_RSTEMP m6 : 30|1@1+ (1,0) [0|0] "" Vector__XXX
 SG_ TRCM_LEFT_C_PILLAR_ACCEL_RSTEMP m8 : 30|1@1+ (1,0) [0|0] "" Vector__XXX
 SG_ TRCM_REAR_LEFT_DOOR_PRESSURE_RSTEMP m11 : 30|1@1+ (1,0) [0|0] "" Vector__XXX
 SG_ TRCM_REAR_RIGHT_DOOR_PRESSURE_RSTEMP m10 : 30|1@1+ (1,0) [0|0] "" Vector__XXX
 SG_ TRCM_RIGHT_B_PILLAR_ACCEL_RSTEMP m5 : 30|1@1+ (1,0) [0|0] "" Vector__XXX
 SG_ TRCM_RIGHT_C_PILLAR_ACCEL_RSTEMP m9 : 30|1@1+ (1,0) [0|0] "" Vector__XXX
 SG_ TRCM_onboardAccelZLowRangeNotOkay m22 : 30|1@1+ (1,0) [0|0] "" Vector__XXX
 SG_ TRCM_FRONT_CENTER_ACCEL_CH_OFF m7 : 31|1@1+ (1,0) [0|0] "" Vector__XXX
 SG_ TRCM_FRONT_CENTER_ACCEL_X_CH_OFF m12 : 31|1@1+ (1,0) [0|0] "" Vector__XXX
 SG_ TRCM_FRONT_CENTER_ACCEL_Y_CH_OFF m13 : 31|1@1+ (1,0) [0|0] "" Vector__XXX
 SG_ TRCM_FRONT_LEFT_ACCEL_CH_OFF m3 : 31|1@1+ (1,0) [0|0] "" Vector__XXX
 SG_ TRCM_FRONT_LEFT_DOOR_PRESSURE_CH_OFF m4 : 31|1@1+ (1,0) [0|0] "" Vector__XXX
 SG_ TRCM_FRONT_RIGHT_ACCEL_CH_OFF m1 : 31|1@1+ (1,0) [0|0] "" Vector__XXX
 SG_ TRCM_FRONT_RIGHT_DOOR_PRESSURE_CH_OFF m2 : 31|1@1+ (1,0) [0|0] "" Vector__XXX
 SG_ TRCM_LEFT_B_PILLAR_ACCEL_CH_OFF m6 : 31|1@1+ (1,0) [0|0] "" Vector__XXX
 SG_ TRCM_LEFT_C_PILLAR_ACCEL_CH_OFF m8 : 31|1@1+ (1,0) [0|0] "" Vector__XXX
 SG_ TRCM_REAR_LEFT_DOOR_PRESSURE_CH_OFF m11 : 31|1@1+ (1,0) [0|0] "" Vector__XXX
 SG_ TRCM_REAR_RIGHT_DOOR_PRESSURE_CH_OFF m10 : 31|1@1+ (1,0) [0|0] "" Vector__XXX
 SG_ TRCM_RIGHT_B_PILLAR_ACCEL_CH_OFF m5 : 31|1@1+ (1,0) [0|0] "" Vector__XXX
 SG_ TRCM_RIGHT_C_PILLAR_ACCEL_CH_OFF m9 : 31|1@1+ (1,0) [0|0] "" Vector__XXX
 SG_ TRCM_onboardAccelXHighRangeNotOkay m22 : 31|1@1+ (1,0) [0|0] "" Vector__XXX
 SG_ TRCM_FRONT_CENTER_ACCEL_State m7 : 32|4@1+ (1,0) [0|0] "" Vector__XXX
 SG_ TRCM_FRONT_CENTER_ACCEL_X_State m12 : 32|4@1+ (1,0) [0|0] "" Vector__XXX
 SG_ TRCM_FRONT_CENTER_ACCEL_Y_State m13 : 32|4@1+ (1,0) [0|0] "" Vector__XXX
 SG_ TRCM_FRONT_LEFT_ACCEL_State m3 : 32|4@1+ (1,0) [0|0] "" Vector__XXX
 SG_ TRCM_FRONT_LEFT_DOOR_PRESSURE_State m4 : 32|4@1+ (1,0) [0|0] "" Vector__XXX
 SG_ TRCM_FRONT_RIGHT_ACCEL_State m1 : 32|4@1+ (1,0) [0|0] "" Vector__XXX
 SG_ TRCM_FRONT_RIGHT_DOOR_PRESSURE_State m2 : 32|4@1+ (1,0) [0|0] "" Vector__XXX
 SG_ TRCM_HerculesLogNumber m19 : 32|4@1+ (1,0) [0|0] "" Vector__XXX
 SG_ TRCM_LEFT_B_PILLAR_ACCEL_State m6 : 32|4@1+ (1,0) [0|0] "" Vector__XXX
 SG_ TRCM_LEFT_C_PILLAR_ACCEL_State m8 : 32|4@1+ (1,0) [0|0] "" Vector__XXX
 SG_ TRCM_REAR_LEFT_DOOR_PRESSURE_State m11 : 32|4@1+ (1,0) [0|0] "" Vector__XXX
 SG_ TRCM_REAR_RIGHT_DOOR_PRESSURE_State m10 : 32|4@1+ (1,0) [0|0] "" Vector__XXX
 SG_ TRCM_RIGHT_B_PILLAR_ACCEL_State m5 : 32|4@1+ (1,0) [0|0] "" Vector__XXX
 SG_ TRCM_RIGHT_C_PILLAR_ACCEL_State m9 : 32|4@1+ (1,0) [0|0] "" Vector__XXX
 SG_ TRCM_deployCommandCount m21 : 32|8@1+ (1,0) [0|0] "" Vector__XXX
 SG_ TRCM_deploymentLoopResistance10 m15 : 32|8@1+ (0.05,0) [0|0] "" Vector__XXX
 SG_ TRCM_deploymentLoopResistance17 m16 : 32|8@1+ (0.05,0) [0|0] "" Vector__XXX
 SG_ TRCM_deploymentLoopResistance24 m17 : 32|8@1+ (0.05,0) [0|0] "" Vector__XXX
 SG_ TRCM_deploymentLoopResistance3 m14 : 32|8@1+ (0.05,0) [0|0] "" Vector__XXX
 SG_ TRCM_deploymentLoopResistance31 m18 : 32|8@1+ (0.05,0) [0|0] "" Vector__XXX
 SG_ TRCM_extenderAsic2Temp m20 : 32|8@1+ (1,-40) [0|0] "" Vector__XXX
 SG_ TRCM_glacierFaultReason m0 : 32|5@1+ (1,0) [0|0] "" Vector__XXX
 SG_ TRCM_onboardAccelYHighRangeNotOkay m22 : 32|1@1+ (1,0) [0|0] "" Vector__XXX
 SG_ TRCM_onboardAngularRateXNotOkay m22 : 33|1@1+ (1,0) [0|0] "" Vector__XXX
 SG_ TRCM_onboardAngularRateYNotOkay m22 : 34|1@1+ (1,0) [0|0] "" Vector__XXX
 SG_ TRCM_onboardAngularRateZNotOkay m22 : 35|1@1+ (1,0) [0|0] "" Vector__XXX
 SG_ TRCM_EDREventState m19 : 36|3@1+ (1,0) [0|0] "" Vector__XXX
 SG_ TRCM_FRONT_CENTER_ACCEL_BaseCurrent m7 : 36|9@1- (0.1875,0) [0|0] "" Vector__XXX
 SG_ TRCM_FRONT_CENTER_ACCEL_X_BaseCurrent m12 : 36|9@1- (0.1875,0) [0|0] "" Vector__XXX
 SG_ TRCM_FRONT_CENTER_ACCEL_Y_BaseCurrent m13 : 36|9@1- (0.1875,0) [0|0] "" Vector__XXX
 SG_ TRCM_FRONT_LEFT_ACCEL_BaseCurrent m3 : 36|9@1- (0.1875,0) [0|0] "" Vector__XXX
 SG_ TRCM_FRONT_LEFT_DOOR_PRESSURE_BaseCurrent m4 : 36|9@1- (0.1875,0) [0|0] "" Vector__XXX
 SG_ TRCM_FRONT_RIGHT_ACCEL_BaseCurrent m1 : 36|9@1- (0.1875,0) [0|0] "" Vector__XXX
 SG_ TRCM_FRONT_RIGHT_DOOR_PRESSURE_BaseCurrent m2 : 36|9@1- (0.1875,0) [0|0] "" Vector__XXX
 SG_ TRCM_LEFT_B_PILLAR_ACCEL_BaseCurrent m6 : 36|9@1- (0.1875,0) [0|0] "" Vector__XXX
 SG_ TRCM_LEFT_C_PILLAR_ACCEL_BaseCurrent m8 : 36|9@1- (0.1875,0) [0|0] "" Vector__XXX
 SG_ TRCM_REAR_LEFT_DOOR_PRESSURE_BaseCurrent m11 : 36|9@1- (0.1875,0) [0|0] "" Vector__XXX
 SG_ TRCM_REAR_RIGHT_DOOR_PRESSURE_BaseCurrent m10 : 36|9@1- (0.1875,0) [0|0] "" Vector__XXX
 SG_ TRCM_RIGHT_B_PILLAR_ACCEL_BaseCurrent m5 : 36|9@1- (0.1875,0) [0|0] "" Vector__XXX
 SG_ TRCM_RIGHT_C_PILLAR_ACCEL_BaseCurrent m9 : 36|9@1- (0.1875,0) [0|0] "" Vector__XXX
 SG_ TRCM_edrLogAreaLocked m22 : 36|1@1+ (1,0) [0|0] "" Vector__XXX
 SG_ TRCM_asm5State m0 : 37|4@1+ (1,0) [0|0] "" Vector__XXX
 SG_ TRCM_imuUncalibrated m22 : 37|1@1+ (1,0) [0|0] "" Vector__XXX
 SG_ TRCM_frontCenterAccelNotOkay m22 : 38|1@1+ (1,0) [0|0] "" Vector__XXX
 SG_ TRCM_frontLeftAccelNotOkay m22 : 39|1@1+ (1,0) [0|0] "" Vector__XXX
 SG_ TRCM_EDRRecorderState m19 : 40|3@1+ (1,0) [0|0] "" Vector__XXX
 SG_ TRCM_asm3Temp m20 : 40|8@1+ (1,-40) [0|0] "" Vector__XXX
 SG_ TRCM_deployInvalidCount m21 : 40|2@1+ (1,0) [0|0] "" Vector__XXX
 SG_ TRCM_deploymentLoopResistance11 m15 : 40|8@1+ (0.05,0) [0|0] "" Vector__XXX
 SG_ TRCM_deploymentLoopResistance18 m16 : 40|8@1+ (0.05,0) [0|0] "" Vector__XXX
 SG_ TRCM_deploymentLoopResistance25 m17 : 40|8@1+ (0.05,0) [0|0] "" Vector__XXX
 SG_ TRCM_deploymentLoopResistance4 m14 : 40|8@1+ (0.05,0) [0|0] "" Vector__XXX
 SG_ TRCM_frontRightAccelNotOkay m22 : 40|1@1+ (1,0) [0|0] "" Vector__XXX
 SG_ TRCM_asm3State m0 : 41|4@1+ (1,0) [0|0] "" Vector__XXX
 SG_ TRCM_leftBPillarAccelNotOkay m22 : 41|1@1+ (1,0) [0|0] "" Vector__XXX
 SG_ TRCM_rightBPillarAccelNotOkay m22 : 42|1@1+ (1,0) [0|0] "" Vector__XXX
 SG_ TRCM_safingMonitorError m21 : 42|3@1+ (1,0) [0|0] "" Vector__XXX
 SG_ TRCM_LastLogIdSaved m19 : 43|8@1+ (1,0) [0|0] "" Vector__XXX
 SG_ TRCM_frontLeftDoorPressureNotOkay m22 : 43|1@1+ (1,0) [0|0] "" Vector__XXX
 SG_ TRCM_frontRightDoorPressureNotOkay m22 : 44|1@1+ (1,0) [0|0] "" Vector__XXX
 SG_ TRCM_ais2120State m0 : 45|4@1+ (1,0) [0|0] "" Vector__XXX
 SG_ TRCM_leftCPillarAccelNotOkay m22 : 45|1@1+ (1,0) [0|0] "" Vector__XXX
 SG_ TRCM_rightCPillarAccelNotOkay m22 : 46|1@1+ (1,0) [0|0] "" Vector__XXX
 SG_ TRCM_ens1NotOkay m22 : 47|1@1+ (1,0) [0|0] "" Vector__XXX
 SG_ TRCM_asm5Temp m20 : 48|8@1+ (1,-40) [0|0] "" Vector__XXX
 SG_ TRCM_deploymentLoopResistance12 m15 : 48|8@1+ (0.05,0) [0|0] "" Vector__XXX
 SG_ TRCM_deploymentLoopResistance19 m16 : 48|8@1+ (0.05,0) [0|0] "" Vector__XXX
 SG_ TRCM_deploymentLoopResistance26 m17 : 48|8@1+ (0.05,0) [0|0] "" Vector__XXX
 SG_ TRCM_deploymentLoopResistance5 m14 : 48|8@1+ (0.05,0) [0|0] "" Vector__XXX
 SG_ TRCM_ens2NotOkay m22 : 48|1@1+ (1,0) [0|0] "" Vector__XXX
 SG_ TRCM_sysPowerCycles m21 : 48|8@1+ (1,0) [0|0] "" Vector__XXX
 SG_ TRCM_airbagAsicsRsspiState m0 : 49|6@1+ (1,0) [0|0] "" Vector__XXX
 SG_ TRCM_LastLogIdUploaded m19 : 51|8@1+ (1,0) [0|0] "" Vector__XXX
 SG_ TRCM_scrapDeploymentState m0 : 55|4@1+ (1,0) [0|0] "" Vector__XXX
 SG_ TRCM_algoState m21 : 56|3@1+ (1,0) [0|0] "" Vector__XXX
 SG_ TRCM_deploymentLoopResistance13 m15 : 56|8@1+ (0.05,0) [0|0] "" Vector__XXX
 SG_ TRCM_deploymentLoopResistance20 m16 : 56|8@1+ (0.05,0) [0|0] "" Vector__XXX
 SG_ TRCM_deploymentLoopResistance27 m17 : 56|8@1+ (0.05,0) [0|0] "" Vector__XXX
 SG_ TRCM_deploymentLoopResistance6 m14 : 56|8@1+ (0.05,0) [0|0] "" Vector__XXX
 SG_ TRCM_microcontrollerTemp m20 : 56|8@1+ (1,-40) [0|0] "" Vector__XXX
 SG_ TRCM_NvmStatus m19 : 59|4@1+ (1,0) [0|0] "" Vector__XXX
 SG_ TRCM_watchdogErrorCounter m0 : 59|4@1+ (1,0) [0|0] "" Vector__XXX

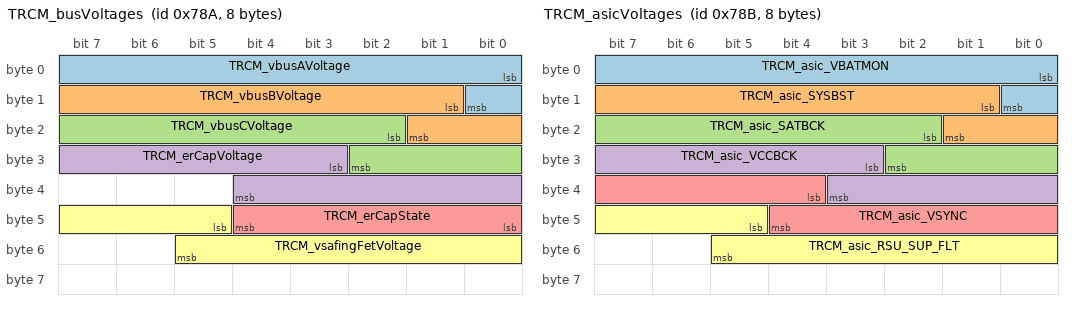
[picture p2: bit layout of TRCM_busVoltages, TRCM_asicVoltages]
BO_ 1930 TRCM_busVoltages: 8 Vector__XXX
 SG_ TRCM_vbusAVoltage : 0|9@1+ (0.05,0) [0|0] "" Vector__XXX
 SG_ TRCM_vbusBVoltage : 9|9@1+ (0.05,0) [0|0] "" Vector__XXX
 SG_ TRCM_vbusCVoltage : 18|9@1+ (0.05,0) [0|0] "" Vector__XXX
 SG_ TRCM_erCapVoltage : 27|10@1+ (0.04,0) [0|0] "" Vector__XXX
 SG_ TRCM_erCapState : 40|5@1+ (1,0) [0|0] "" Vector__XXX
 SG_ TRCM_vsafingFetVoltage : 45|9@1+ (0.05,0) [0|0] "" Vector__XXX

BO_ 1931 TRCM_asicVoltages: 8 Vector__XXX
 SG_ TRCM_asic_VBATMON : 0|9@1+ (0.05,0) [0|0] "" Vector__XXX
 SG_ TRCM_asic_SYSBST : 9|9@1+ (0.05,0) [0|0] "" Vector__XXX
 SG_ TRCM_asic_SATBCK : 18|9@1+ (0.05,0) [0|0] "" Vector__XXX
 SG_ TRCM_asic_VCCBCK : 27|9@1+ (0.05,0) [0|0] "" Vector__XXX
 SG_ TRCM_asic_VSYNC : 36|9@1+ (0.05,0) [0|0] "" Vector__XXX
 SG_ TRCM_asic_RSU_SUP_FLT : 45|9@1+ (0.05,0) [0|0] "" Vector__XXX

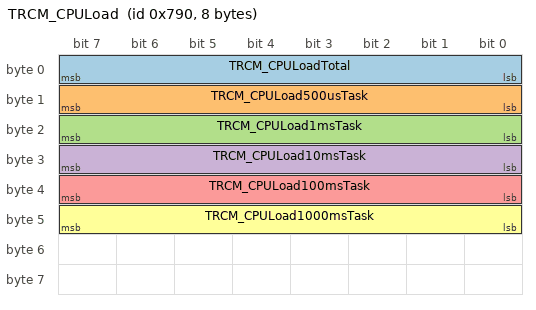
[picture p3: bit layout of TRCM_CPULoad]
BO_ 1936 TRCM_CPULoad: 8 Vector__XXX
 SG_ TRCM_CPULoadTotal : 0|8@1+ (1,0) [0|0] "" Vector__XXX
 SG_ TRCM_CPULoad500usTask : 8|8@1+ (1,0) [0|0] "" Vector__XXX
 SG_ TRCM_CPULoad1msTask : 16|8@1+ (1,0) [0|0] "" Vector__XXX
 SG_ TRCM_CPULoad10msTask : 24|8@1+ (1,0) [0|0] "" Vector__XXX
 SG_ TRCM_CPULoad100msTask : 32|8@1+ (1,0) [0|0] "" Vector__XXX
 SG_ TRCM_CPULoad1000msTask : 40|8@1+ (1,0) [0|0] "" Vector__XXX

BO_ 1971 UI_dynamicTriggersCampaignFired: 8 Vector__XXX
 SG_ UI_campaignFired : 0|64@1+ (1,0) [0|0] "" Vector__XXX

BO_ 2015 UDS_functionalRequest_CH: 12 Vector__XXX
 SG_ UDS_functionalRequestDataCH : 7|64@0+ (1,0) [0|0] "" Vector__XXX

BO_ 2031 DBG_testMessage: 8 Vector__XXX
 SG_ DBG_testID : 0|16@1+ (1,0) [0|0] "" Vector__XXX

BO_ 2047 GTW_carConfig: 8 Vector__XXX
 SG_ GTW_carConfigMultiplexer M : 0|8@1+ (1,0) [0|0] "" Vector__XXX
 SG_ GTW_birthday m4 : 8|32@1+ (1,0) [0|0] "" Vector__XXX
 SG_ GTW_deliveryStatus m1 : 8|1@1+ (1,0) [0|0] "" Vector__XXX
 SG_ GTW_exteriorTrimType m2 : 8|1@1+ (1,0) [0|0] "" Vector__XXX
 SG_ GTW_gloveboxUSBType m5 : 8|2@1+ (1,0) [0|0] "" Vector__XXX
 SG_ GTW_mapRegion m3 : 8|4@1+ (1,0) [0|0] "" Vector__XXX
 SG_ GTW_rcmUndersideAbuseZThreshold m9 : 8|3@1+ (1,0) [0|0] "" Vector__XXX
 SG_ GTW_fasciaType m7 : 9|4@1+ (1,0) [0|0] "" Vector__XXX
 SG_ GTW_frontSeatHeaters m2 : 9|1@1+ (1,0) [0|0] "" Vector__XXX
 SG_ GTW_wiperMotorType m6 : 9|1@1+ (1,0) [0|0] "" Vector__XXX
 SG_ GTW_cabinPTCHeaterType m1 : 10|1@1+ (1,0) [0|0] "" Vector__XXX
 SG_ GTW_coolantPumpType m5 : 10|3@1+ (1,0) [0|0] "" Vector__XXX
 SG_ GTW_frontOverheadConsoleType m6 : 10|2@1+ (1,0) [0|0] "" Vector__XXX
 SG_ GTW_rearSeatHeaters m2 : 10|1@1+ (1,0) [0|0] "" Vector__XXX
 SG_ GTW_sohRegulatoryStatus m8 : 10|1@1+ (1,0) [0|0] "" Vector__XXX
 SG_ GTW_rcmUndersideAbuseYThreshold m9 : 11|3@1+ (1,0) [0|0] "" Vector__XXX
 SG_ GTW_rightHandDrive m1 : 11|1@1+ (1,0) [0|0] "" Vector__XXX
 SG_ GTW_eCallAntennaHW m2 : 12|1@1+ (1,0) [0|0] "" Vector__XXX
 SG_ GTW_performancePackage m3 : 12|3@1+ (1,0) [0|0] "" Vector__XXX
 SG_ GTW_rearLightType m1 : 12|2@1+ (1,0) [0|0] "" Vector__XXX
 SG_ GTW_shifterType m6 : 12|1@1+ (1,0) [0|0] "" Vector__XXX
 SG_ GTW_compressorType m6 : 13|4@1+ (1,0) [0|0] "" Vector__XXX
 SG_ GTW_epblHwType m5 : 13|4@1+ (1,0) [0|0] "" Vector__XXX
 SG_ GTW_homelinkType m2 : 13|1@1+ (1,0) [0|0] "" Vector__XXX
 SG_ GTW_powerSteeringColumn m7 : 13|1@1+ (1,0) [0|0] "" Vector__XXX
 SG_ GTW_frontSeatHeaterType m7 : 14|1@1+ (1,0) [0|0] "" Vector__XXX
 SG_ GTW_headlamps m1 : 14|2@1+ (1,0) [0|0] "" Vector__XXX
 SG_ GTW_rcmUndersideAbuseWindow m9 : 14|2@1+ (1,0) [0|0] "" Vector__XXX
 SG_ GTW_vdcType m2 : 14|1@1+ (1,0) [0|0] "" Vector__XXX
 SG_ GTW_softPerformanceLimit m7 : 15|4@1+ (1,0) [0|0] "" Vector__XXX
 SG_ GTW_country m1 : 16|16@1+ (1,0) [0|0] "" Vector__XXX
 SG_ GTW_epbrHwType m5 : 17|4@1+ (1,0) [0|0] "" Vector__XXX
 SG_ GTW_m3yBusArchitecture m8 : 17|2@1+ (1,0) [0|0] "" Vector__XXX
 SG_ GTW_memoryMirrors m2 : 17|1@1+ (1,0) [0|0] "" Vector__XXX
 SG_ GTW_twelveVBatteryType m6 : 17|3@1+ (1,0) [0|0] "" Vector__XXX
 SG_ GTW_chassisType m3 : 18|4@1+ (1,0) [0|0] "" Vector__XXX
 SG_ GTW_powerLiftgateType m2 : 18|2@1+ (1,0) [0|0] "" Vector__XXX
 SG_ GTW_efuseSWConfig m6 : 20|3@1+ (1,0) [0|0] "" Vector__XXX
 SG_ GTW_lumbarECUType m2 : 20|4@1+ (1,0) [0|0] "" Vector__XXX
 SG_ GTW_blowerMotorType m5 : 21|2@1+ (1,0) [0|0] "" Vector__XXX
 SG_ GTW_interiorUpperTrimType m8 : 21|1@1+ (1,0) [0|0] "" Vector__XXX
 SG_ GTW_airSuspension m3 : 22|2@1+ (1,0) [0|0] "" Vector__XXX
 SG_ GTW_alcoholInterlockType m7 : 22|1@1+ (1,0) [0|0] "" Vector__XXX
 SG_ GTW_blindSpotIndicatorLightType m8 : 22|2@1+ (1,0) [0|0] "" Vector__XXX
 SG_ GTW_immersiveAudio m7 : 23|2@1+ (1,0) [0|0] "" Vector__XXX
 SG_ GTW_bleEndpointUpdateMethod m6 : 24|1@1+ (1,0) [0|0] "" Vector__XXX
 SG_ GTW_centerConsoleControllerType m3 : 24|2@1+ (1,0) [0|0] "" Vector__XXX
 SG_ GTW_powerMirrorFoldType m5 : 24|1@1+ (1,0) [0|0] "" Vector__XXX
 SG_ GTW_rearSeatHeaterType m2 : 24|2@1+ (1,0) [0|0] "" Vector__XXX
 SG_ GTW_wiperMotorAsicType m8 : 24|2@1+ (1,0) [0|0] "" Vector__XXX
 SG_ GTW_steeringWheelControllerType m6 : 25|3@1+ (1,0) [0|0] "" Vector__XXX
 SG_ GTW_autopilotCameraType m3 : 26|1@1+ (1,0) [0|0] "" Vector__XXX
 SG_ GTW_auxParkLamps m2 : 26|2@1+ (1,0) [0|0] "" Vector__XXX
 SG_ GTW_passengerOccupancySensorType m7 : 26|3@1+ (1,0) [0|0] "" Vector__XXX
 SG_ GTW_connectivityPackage m3 : 27|1@1+ (1,0) [0|0] "" Vector__XXX
 SG_ GTW_frontUsbHubType m5 : 27|3@1+ (1,0) [0|0] "" Vector__XXX
 SG_ GTW_interiorCabinRadarType m2 : 28|1@1+ (1,0) [0|0] "" Vector__XXX
 SG_ GTW_plcSupportType m3 : 28|2@1+ (1,0) [0|0] "" Vector__XXX
 SG_ GTW_gloveboxActuatorType m6 : 29|2@1+ (1,0) [0|0] "" Vector__XXX
 SG_ GTW_hvacPanelVaneType m2 : 29|1@1+ (1,0) [0|0] "" Vector__XXX
 SG_ GTW_badgingVersion m3 : 30|2@1+ (1,0) [0|0] "" Vector__XXX
 SG_ GTW_packPerformanceDeviation m7 : 30|3@1+ (1,0) [0|0] "" Vector__XXX
 SG_ GTW_superManifoldType m5 : 30|2@1+ (1,0) [0|0] "" Vector__XXX
 SG_ GTW_rduCableType m8 : 31|1@1+ (1,0) [0|0] "" Vector__XXX
 SG_ GTW_eBuckConfig m2 : 32|1@1+ (1,0) [0|0] "" Vector__XXX
 SG_ GTW_epasType m6 : 32|4@1+ (1,0) [0|0] "" Vector__XXX
 SG_ GTW_packEnergy m3 : 32|5@1+ (1,0) [0|0] "" Vector__XXX
 SG_ GTW_parkTelltaleBehaviorType m8 : 32|1@1+ (1,0) [0|0] "" Vector__XXX
 SG_ GTW_rcmLocation m5 : 32|1@1+ (1,0) [0|0] "" Vector__XXX
 SG_ GTW_tireType m1 : 32|6@1+ (1,0) [0|0] "" Vector__XXX
 SG_ GTW_autopilotExteriorCameraType m5 : 33|1@1+ (1,0) [0|0] "" Vector__XXX
 SG_ GTW_epasSubType m9 : 33|1@1+ (1,0) [0|0] "" Vector__XXX
 SG_ GTW_steeringHeaterEnabled m2 : 33|1@1+ (1,0) [0|0] "" Vector__XXX
 SG_ GTW_activeHighBeam m2 : 34|1@1+ (1,0) [0|0] "" Vector__XXX
 SG_ GTW_airbagCutoffSwitch m2 : 35|1@1+ (1,0) [0|0] "" Vector__XXX
 SG_ GTW_frontFogLamps m7 : 35|1@1+ (1,0) [0|0] "" Vector__XXX
 SG_ GTW_wiperSupplyChainOrigin m9 : 35|2@1+ (1,0) [0|0] "" Vector__XXX
 SG_ GTW_homologationRegionOverride m6 : 36|2@1+ (1,0) [0|0] "" Vector__XXX
 SG_ GTW_intrusionSensorType m2 : 36|1@1+ (1,0) [0|0] "" Vector__XXX
 SG_ GTW_audioType m7 : 37|3@1+ (1,0) [0|0] "" Vector__XXX
 SG_ GTW_frontSeatReclinerHardware m3 : 37|2@1+ (1,0) [0|0] "" Vector__XXX
 SG_ GTW_sirenType m5 : 37|1@1+ (1,0) [0|0] "" Vector__XXX
 SG_ GTW_spoilerType m2 : 37|1@1+ (1,0) [0|0] "" Vector__XXX
 SG_ GTW_hornType m5 : 38|1@1+ (1,0) [0|0] "" Vector__XXX
 SG_ GTW_roofGlassType m1 : 38|2@1+ (1,0) [0|0] "" Vector__XXX
 SG_ GTW_windowCommandsPermissionType m6 : 38|2@1+ (1,0) [0|0] "" Vector__XXX
 SG_ GTW_brakeLineSwitchType m3 : 39|1@1+ (1,0) [0|0] "" Vector__XXX
 SG_ GTW_interiorCameraType m8 : 39|2@1+ (1,0) [0|0] "" Vector__XXX
 SG_ GTW_rearFogLamps m2 : 39|1@1+ (1,0) [0|0] "" Vector__XXX
 SG_ GTW_dasHw m1 : 40|3@1+ (1,0) [0|0] "" Vector__XXX
 SG_ GTW_eCallEnabled m4 : 40|2@1+ (1,0) [0|0] "" Vector__XXX
 SG_ GTW_espValveType m3 : 40|2@1+ (1,0) [0|0] "" Vector__XXX
 SG_ GTW_mRecordVersion m9 : 40|1@1+ (1,0) [0|0] "" Vector__XXX
 SG_ GTW_roofType m2 : 40|1@1+ (1,0) [0|0] "" Vector__XXX
 SG_ GTW_frontFasciaCameraType m8 : 41|2@1+ (1,0) [0|0] "" Vector__XXX
 SG_ GTW_autopilot m2 : 42|3@1+ (1,0) [0|0] "" Vector__XXX
 SG_ GTW_headlightStepperStallDetectMode m6 : 42|1@1+ (1,0) [0|0] "" Vector__XXX
 SG_ GTW_parkAssistECUType m4 : 42|2@1+ (1,0) [0|0] "" Vector__XXX
 SG_ GTW_softRange m3 : 42|3@1+ (1,0) [0|0] "" Vector__XXX
 SG_ GTW_steeringColumnMotorType m5 : 42|2@1+ (1,0) [0|0] "" Vector__XXX
 SG_ GTW_brakeHWType m1 : 43|5@1+ (1,0) [0|0] "" Vector__XXX
 SG_ GTW_rgbInteriorLightingEnabled m6 : 43|2@1+ (1,0) [0|0] "" Vector__XXX
 SG_ GTW_passengerAirbagType m4 : 44|2@1+ (1,0) [0|0] "" Vector__XXX
 SG_ GTW_interiorCamFanType m8 : 45|3@1+ (1,0) [0|0] "" Vector__XXX
 SG_ GTW_refrigerantType m3 : 45|2@1+ (1,0) [0|0] "" Vector__XXX
 SG_ GTW_superchargingAccess m2 : 45|2@1+ (1,0) [0|0] "" Vector__XXX
 SG_ GTW_windshieldWiperHeaterType m6 : 45|1@1+ (1,0) [0|0] "" Vector__XXX
 SG_ GTW_forwardRadarHw m4 : 46|2@1+ (1,0) [0|0] "" Vector__XXX
 SG_ GTW_frontControllerArchitectureType m7 : 46|1@1+ (1,0) [0|0] "" Vector__XXX
 SG_ GTW_driveInterfaceType m6 : 47|1@1+ (1,0) [0|0] "" Vector__XXX
 SG_ GTW_exteriorColor m2 : 48|5@1+ (1,0) [0|0] "" Vector__XXX
 SG_ GTW_frontSeatType m4 : 48|4@1+ (1,0) [0|0] "" Vector__XXX
 SG_ GTW_refrigACLineType m5 : 48|2@1+ (1,0) [0|0] "" Vector__XXX
 SG_ GTW_restraintsHardwareType m1 : 48|8@1+ (1,0) [0|0] "" Vector__XXX
 SG_ GTW_wheelType m3 : 48|7@1+ (1,0) [0|0] "" Vector__XXX
 SG_ GTW_efficiencyPackage m6 : 49|6@1+ (1,0) [0|0] "" Vector__XXX
 SG_ GTW_tpmsType m7 : 49|2@1+ (1,0) [0|0] "" Vector__XXX
 SG_ GTW_refrigFilterType m5 : 50|2@1+ (1,0) [0|0] "" Vector__XXX
 SG_ GTW_authenticationEndpointLayout m7 : 52|3@1+ (1,0) [0|0] "" Vector__XXX
 SG_ GTW_diBurnInType m5 : 52|1@1+ (1,0) [0|0] "" Vector__XXX
 SG_ GTW_pedestrianWarningSound m2 : 53|2@1+ (1,0) [0|0] "" Vector__XXX
 SG_ GTW_specialBadgingType m5 : 53|2@1+ (1,0) [0|0] "" Vector__XXX
 SG_ GTW_wirelessPhoneChargerType m4 : 53|2@1+ (1,0) [0|0] "" Vector__XXX
 SG_ GTW_chassisSubType m5 : 55|2@1+ (1,0) [0|0] "" Vector__XXX
 SG_ GTW_ethernetTunerType m4 : 55|2@1+ (1,0) [0|0] "" Vector__XXX
 SG_ GTW_ptcControlMode m3 : 55|2@1+ (1,0) [0|0] "" Vector__XXX
 SG_ GTW_steeringColumnUJointType m2 : 55|1@1+ (1,0) [0|0] "" Vector__XXX
 SG_ GTW_visorLightType m6 : 55|1@1+ (1,0) [0|0] "" Vector__XXX
 SG_ GTW_bPillarNFCParam m2 : 56|1@1+ (1,0) [0|0] "" Vector__XXX
 SG_ GTW_drivetrainType m1 : 56|4@1+ (1,0) [0|0] "" Vector__XXX
 SG_ GTW_brakeActuationType m3 : 57|3@1+ (1,0) [0|0] "" Vector__XXX
 SG_ GTW_frontSeatVentilationType m5 : 57|1@1+ (1,0) [0|0] "" Vector__XXX
 SG_ GTW_interiorLighting m2 : 57|3@1+ (1,0) [0|0] "" Vector__XXX
 SG_ GTW_socSleepOverride m7 : 57|2@1+ (1,0) [0|0] "" Vector__XXX
 SG_ GTW_gnssAntennaType m6 : 58|2@1+ (1,0) [0|0] "" Vector__XXX
 SG_ GTW_towPackage m5 : 58|2@1+ (1,0) [0|0] "" Vector__XXX
 SG_ GTW_v2xEnabled m9 : 58|1@1+ (1,0) [0|0] "" Vector__XXX
 SG_ GTW_r79BehaviorOverride m7 : 59|1@1+ (1,0) [0|0] "" Vector__XXX
 SG_ GTW_headlightLevelerType m2 : 60|2@1+ (1,0) [0|0] "" Vector__XXX
 SG_ GTW_interiorTrimType m4 : 60|4@1+ (1,0) [0|0] "" Vector__XXX
 SG_ GTW_radarHeaterType m1 : 60|3@1+ (1,0) [0|0] "" Vector__XXX
 SG_ GTW_repeaterAeroRibType m8 : 60|3@1+ (1,0) [0|0] "" Vector__XXX
 SG_ GTW_steeringHeaterType m7 : 60|3@1+ (1,0) [0|0] "" Vector__XXX
 SG_ GTW_restraintControlsType m5 : 61|1@1+ (1,0) [0|0] "" Vector__XXX
 SG_ GTW_caliperColorType m5 : 62|2@1+ (1,0) [0|0] "" Vector__XXX
 SG_ GTW_frontSeatHeatersEnabled m6 : 62|1@1+ (1,0) [0|0] "" Vector__XXX
 SG_ GTW_numberHVILNodes m2 : 62|2@1+ (1,0) [0|0] "" Vector__XXX
 SG_ GTW_narrowWipingSupported m7 : 63|1@1+ (1,0) [0|0] "" Vector__XXX
 SG_ GTW_windshieldWiperHeaterEnabled m6 : 63|1@1+ (1,0) [0|0] "" Vector__XXX

VAL_ 1824 DAS_LCM_CIPV_dx 255 "SNA" ;
VAL_ 1824 DAS_SCA_state 0 "STANDBY" 1 "DRIVE" 2 "SUPPORT" 3 "CHARGE" 4 "FEIM" 5 "CLEAR_FAULT" 6 "FAULT" 7 "WELD" 8 "TEST" 9 "SNA" 10 "DIAG" ;
VAL_ 1824 DAS_VWall_Right_type 0 "US_TESLA" 1 "EURO_IEC" 2 "GB" 3 "IEC_CCS" ;
VAL_ 1824 DAS_csa_internal_state 0 "STANDBY" 1 "DRIVE" 2 "SUPPORT" 3 "CHARGE" 4 "FEIM" 5 "CLEAR_FAULT" 6 "FAULT" 7 "WELD" 8 "TEST" 9 "SNA" 10 "DIAG" ;
VAL_ 1824 DAS_FCM_state 0 "STANDBY" 1 "DRIVE" 2 "SUPPORT" 3 "CHARGE" 4 "FEIM" 5 "CLEAR_FAULT" 6 "FAULT" 7 "WELD" 8 "TEST" 9 "SNA" 10 "DIAG" ;
VAL_ 1824 DAS_TFL_jnc_status 0 "DISABLED" 1 "ENABLED" 2 "TEMPORARY_FAILURE" 3 "SNA" ;
VAL_ 1824 DAS_SP_status 0 "DISABLED" 1 "ENABLED" 2 "TEMPORARY_FAILURE" 3 "SNA" ;
VAL_ 1824 DAS_LCM_state 0 "STANDBY" 1 "DRIVE" 2 "SUPPORT" 3 "CHARGE" 4 "FEIM" 5 "CLEAR_FAULT" 6 "FAULT" 7 "WELD" 8 "TEST" 9 "SNA" 10 "DIAG" ;
VAL_ 1824 DAS_rampType 0 "NONE_SNA" 1 "ENTRANCE" 2 "EXIT" 3 "INTERCHANGE_ENTRANCE" 4 "INTERCHANGE_EXIT" ;
VAL_ 1824 DAS_ACC_tgt_cipv2_controlState 0 "INIT" 1 "CONFIG" 2 "IDLE" 3 "CALIBRATE" 4 "PREPARE_RX" 5 "RX" 6 "CHECK_RX" 7 "READ_RXFIFO" 8 "HANDLE_FOUND" 9 "SLEEP" 10 "FAULT" ;
VAL_ 1824 DAS_ACC_tgt_cipv_controlState 0 "INIT" 1 "CONFIG" 2 "IDLE" 3 "CALIBRATE" 4 "PREPARE_RX" 5 "RX" 6 "CHECK_RX" 7 "READ_RXFIFO" 8 "HANDLE_FOUND" 9 "SLEEP" 10 "FAULT" ;
VAL_ 1824 DAS_ACC_tgt_cutin_controlState 0 "INIT" 1 "CONFIG" 2 "IDLE" 3 "CALIBRATE" 4 "PREPARE_RX" 5 "RX" 6 "CHECK_RX" 7 "READ_RXFIFO" 8 "HANDLE_FOUND" 9 "SLEEP" 10 "FAULT" ;
VAL_ 1824 DAS_ACC_tgt_mcvl_controlState 0 "INIT" 1 "CONFIG" 2 "IDLE" 3 "CALIBRATE" 4 "PREPARE_RX" 5 "RX" 6 "CHECK_RX" 7 "READ_RXFIFO" 8 "HANDLE_FOUND" 9 "SLEEP" 10 "FAULT" ;
VAL_ 1824 DAS_ACC_tgt_mcvr_controlState 0 "INIT" 1 "CONFIG" 2 "IDLE" 3 "CALIBRATE" 4 "PREPARE_RX" 5 "RX" 6 "CHECK_RX" 7 "READ_RXFIFO" 8 "HANDLE_FOUND" 9 "SLEEP" 10 "FAULT" ;
VAL_ 1824 DAS_ACC_Target6_controlState 0 "INIT" 1 "CONFIG" 2 "IDLE" 3 "CALIBRATE" 4 "PREPARE_RX" 5 "RX" 6 "CHECK_RX" 7 "READ_RXFIFO" 8 "HANDLE_FOUND" 9 "SLEEP" 10 "FAULT" ;
VAL_ 1824 DAS_ACC_tgt_cipv2_type 0 "US_TESLA" 1 "EURO_IEC" 2 "GB" 3 "IEC_CCS" ;
VAL_ 1824 DAS_ACC_tgt_cipv_type 0 "US_TESLA" 1 "EURO_IEC" 2 "GB" 3 "IEC_CCS" ;
VAL_ 1824 DAS_ACC_tgt_cutin_type 0 "US_TESLA" 1 "EURO_IEC" 2 "GB" 3 "IEC_CCS" ;
VAL_ 1824 DAS_ACC_tgt_mcvl_type 0 "US_TESLA" 1 "EURO_IEC" 2 "GB" 3 "IEC_CCS" ;
VAL_ 1824 DAS_ACC_tgt_mcvr_type 0 "US_TESLA" 1 "EURO_IEC" 2 "GB" 3 "IEC_CCS" ;
VAL_ 1824 DAS_ACC_Target6_type 0 "US_TESLA" 1 "EURO_IEC" 2 "GB" 3 "IEC_CCS" ;
VAL_ 1824 DAS_ACC_Activate_road_class 0 "SNA" 1 "SUPERCHARGER" 2 "URBANCHARGER" ;
VAL_ 1824 DAS_LCM_CIPV_type 0 "US_TESLA" 1 "EURO_IEC" 2 "GB" 3 "IEC_CCS" ;
VAL_ 1825 DAS_ussSensorIdX 0 "REAR_INNER" 1 "REAR_CORNER" 2 "REAR_SIDE" 3 "FRONT_INNER" 4 "FRONT_CORNER" 5 "FRONT_SIDE" ;
VAL_ 1826 DAS_ussSensorIdY 0 "REAR_INNER" 1 "REAR_CORNER" 2 "REAR_SIDE" 3 "FRONT_INNER" 4 "FRONT_CORNER" 5 "FRONT_SIDE" ;
VAL_ 1827 UI_ussSensorIdX 0 "REAR_INNER" 1 "REAR_CORNER" 2 "REAR_SIDE" 3 "FRONT_INNER" 4 "FRONT_CORNER" 5 "FRONT_SIDE" ;
VAL_ 1829 UI_ussSensorIdY 0 "REAR_INNER" 1 "REAR_CORNER" 2 "REAR_SIDE" 3 "FRONT_INNER" 4 "FRONT_CORNER" 5 "FRONT_SIDE" ;
VAL_ 1929 TRCM_debugSelector 64 "Mux64" 128 "Mux128" 66 "Mux66" 67 "Mux67" 131 "Mux131" 68 "Mux68" 132 "Mux132" 69 "Mux69" 70 "Mux70" 72 "Mux72" 32 "Mux32" 33 "Mux33" 34 "Mux34" 35 "Mux35" 36 "Mux36" 37 "Mux37" 38 "Mux38" 39 "Mux39" 40 "Mux40" 41 "Mux41" 42 "Mux42" 43 "Mux43" 46 "Mux46" 47 "Mux47" 48 "Mux48" 49 "Mux49" 50 "Mux50" 52 "Mux52" 63 "Mux63" ;
VAL_ 1929 TRCM_systemState 0 "UNAVAILABLE" 1 "IDLE" 2 "STANDBY" 3 "FAULT" 4 "ABORT" 5 "ENABLE" ;
VAL_ 2047 GTW_deliveryStatus 0 "NOT_DELIVERED" 1 "DELIVERED" ;
VAL_ 2047 GTW_exteriorTrimType 0 "STANDARD_CHROME" 1 "SATIN_BLACK" ;
VAL_ 2047 GTW_gloveboxUSBType 1 "TSC_USB3_A" ;
VAL_ 2047 GTW_mapRegion 0 "US" 1 "EU" 2 "NONE" 3 "CN" 4 "AU" 5 "JP" 6 "TW" 7 "KR" 8 "ME" 9 "HK" 10 "MO" 11 "SE" ;
VAL_ 2047 GTW_frontSeatHeaters 0 "NONE" 1 "KONGSBERG_LOW_POWER" ;
VAL_ 2047 GTW_cabinPTCHeaterType 1 "NONE" ;
VAL_ 2047 GTW_coolantPumpType 3 "SM6PHAN_OFFBOARD4PSAN" 5 "DUAL_MIX" ;
VAL_ 2047 GTW_rearSeatHeaters 0 "NONE" 1 "KONGSBERG_LOW_POWER" ;
VAL_ 2047 GTW_rightHandDrive 0 "LEFT" 1 "RIGHT" ;
VAL_ 2047 GTW_eCallAntennaHW 0 "BACKUP_OR_MAIN_ANT" 1 "MAIN_ANT_ONLY" ;
VAL_ 2047 GTW_performancePackage 0 "BASE" ;
VAL_ 2047 GTW_rearLightType 0 "NA" 2 "GLOBAL" ;
VAL_ 2047 GTW_compressorType 2 "41CC_11K" 4 "11K_COP1_ENABLED" ;
VAL_ 2047 GTW_epblHwType 6 "MANDO_P2" ;
VAL_ 2047 GTW_homelinkType 0 "NONE" 1 "HOMELINK_V_OPT_2" ;
VAL_ 2047 GTW_powerSteeringColumn 0 "NOT_INSTALLED" 1 "TK" ;
VAL_ 2047 GTW_headlamps 1 "PREMIUM" 2 "GLOBAL" ;
VAL_ 2047 GTW_vdcType 0 "BOSCH_VDC" 1 "TESLA_VDC" ;
VAL_ 2047 GTW_epbrHwType 6 "MANDO_P2" ;
VAL_ 2047 GTW_memoryMirrors 0 "NOT_INSTALLED" 1 "SMR" ;
VAL_ 2047 GTW_twelveVBatteryType 2 "CATL_LI_ION" ;
VAL_ 2047 GTW_chassisType 0 "S_CHASSIS" 1 "X_CHASSIS" ;
VAL_ 2047 GTW_powerLiftgateType 0 "NOT_INSTALLED" 1 "TESLA_REV1" ;
VAL_ 2047 GTW_lumbarECUType 0 "NONE" 1 "ALFMEIER" ;
VAL_ 2047 GTW_blowerMotorType 0 "SHINANO" 1 "DELTA" ;
VAL_ 2047 GTW_airSuspension 2 "TESLA_ADAPTIVE" ;
VAL_ 2047 GTW_immersiveAudio 2 "PREMIUM" ;
VAL_ 2047 GTW_autopilotCameraType 0 "RCCB_CAMERAS" ;
VAL_ 2047 GTW_auxParkLamps 1 "NA_PREMIUM" 2 "EU" ;
VAL_ 2047 GTW_passengerOccupancySensorType 2 "IEE_OCS" ;
VAL_ 2047 GTW_connectivityPackage 0 "BASE" 1 "PREMIUM" ;
VAL_ 2047 GTW_frontUsbHubType 0 "2" 4 "NO_DATA" ;
VAL_ 2047 GTW_plcSupportType 0 "NONE" 1 "ONBOARD_ADAPTER" 2 "NATIVE_CHARGE_PORT" ;
VAL_ 2047 GTW_gloveboxActuatorType 0 "SOLENOID" 1 "SMA" ;
VAL_ 2047 GTW_hvacPanelVaneType 0 "PARALLEL_V1" 1 "CONVERGENT_V1" ;
VAL_ 2047 GTW_badgingVersion 0 "0" 1 "1" ;
VAL_ 2047 GTW_superManifoldType 0 "TYPE0" 1 "TYPE1" 2 "TYPE2" ;
VAL_ 2047 GTW_eBuckConfig 0 "NONE" 1 "DEV_BUCK" ;
VAL_ 2047 GTW_epasType 1 "MANDO_VGR66_GEN3" ;
VAL_ 2047 GTW_packEnergy 3 "P2" ;
VAL_ 2047 GTW_tireType 0 "UNKNOWN" 1 "MICHELIN_ALL_SEASON_18" 2 "MICHELIN_SUMMER_18" 3 "HANKOOK_SUMMER_19" 4 "CONTI_ALL_SEASON_19" 5 "MICHELIN_SUMMER_20" 17 "GOODYEAR_ALL_SEASON_20" 18 "PIRELLI_SUMMER_21" 19 "MICHELIN_ALL_SEASON_21" 20 "PIRELLI_SUMMER_19" 21 "PIRELLI_SUMMER_20" 22 "MICHELIN_SUMMER_21" 23 "CONTI_ALL_SEASON_20" 24 "CONTI_SUMMER_22" 25 "PIRELLI_ALL_SEASON_22" 26 "HANKOOK_ALL_SEASON_18" ;
VAL_ 2047 GTW_steeringHeaterEnabled 0 "DISABLED" 1 "ENABLED" ;
VAL_ 2047 GTW_activeHighBeam 0 "NOT_ACTIVE" 1 "ACTIVE" ;
VAL_ 2047 GTW_airbagCutoffSwitch 0 "DISABLED" 1 "ENABLED" ;
VAL_ 2047 GTW_frontFogLamps 0 "NOT_INSTALLED" 1 "INSTALLED" ;
VAL_ 2047 GTW_intrusionSensorType 0 "NOT_INSTALLED" 1 "VODAFONE" ;
VAL_ 2047 GTW_audioType 1 "PREMIUM" ;
VAL_ 2047 GTW_frontSeatReclinerHardware 0 "STANDARD_RANGE" 1 "RIGHT_SEAT_REDUCED_RANGE" 2 "LEFT_SEAT_REDUCED_RANGE" 3 "LEFT_RIGHT_SEAT_REDUCED_RANGE" ;
VAL_ 2047 GTW_spoilerType 0 "NOT_INSTALLED" 1 "PASSIVE" ;
VAL_ 2047 GTW_hornType 0 "TRUMPET" 1 "EXT_SPEAKER_V2" ;
VAL_ 2047 GTW_roofGlassType 0 "TSA3_PET" 1 "TSA5_NOPET" ;
VAL_ 2047 GTW_brakeLineSwitchType 0 "DI_VC_SHARED" 1 "VC_ONLY" ;
VAL_ 2047 GTW_interiorCameraType 1 "VD6763" ;
VAL_ 2047 GTW_rearFogLamps 0 "NOT_INSTALLED" 1 "INSTALLED" ;
VAL_ 2047 GTW_dasHw 3 "PARKER_PASCAL_2_5" 4 "TESLA_AP3" ;
VAL_ 2047 GTW_eCallEnabled 0 "DISABLED" 1 "ENABLED_OHC_SOS" 2 "ENABLED_UI_SOS" ;
VAL_ 2047 GTW_espValveType 0 "UNKNOWN" 1 "VALVE_TYPE_1" 2 "VALVE_TYPE_2" ;
VAL_ 2047 GTW_roofType 1 "FIXED_GLASS" ;
VAL_ 2047 GTW_autopilot 0 "NONE" 1 "HIGHWAY" 2 "ENHANCED" 3 "SELF_DRIVING" 4 "BASIC" ;
VAL_ 2047 GTW_parkAssistECUType 0 "VALEO" 1 "TESLA" ;
VAL_ 2047 GTW_softRange 0 "STANDARD" ;
VAL_ 2047 GTW_steeringColumnMotorType 0 "BOSCH" 1 "JE" ;
VAL_ 2047 GTW_brakeHWType 4 "D380_MANDO1_43_D365" 5 "D395_MANDO1_43_D365" ;
VAL_ 2047 GTW_passengerAirbagType 0 "FULL_SUPPRESSION" 1 "SAFETY_VENT" 2 "EUROW" ;
VAL_ 2047 GTW_interiorCamFanType 1 "SLEEVE" 2 "FDB" ;
VAL_ 2047 GTW_refrigerantType 0 "Default" 1 "R134A" 2 "R1234YF" ;
VAL_ 2047 GTW_superchargingAccess 0 "NOT_ALLOWED" 1 "ALLOWED" 2 "PAY_AS_YOU_GO" ;
VAL_ 2047 GTW_forwardRadarHw 0 "CONTI_ARS410" 2 "NONE" ;
VAL_ 2047 GTW_exteriorColor 0 "RED_MULTICOAT" 1 "SOLID_BLACK" 3 "MIDNIGHT_SILVER" 5 "DEEP_BLUE" 6 "PEARL_WHITE" ;
VAL_ 2047 GTW_frontSeatType 0 "BASE_TESLA" 1 "PREMIUM_TESLA" 2 "PREMIUM_L_YANFENG_R_TESLA" 3 "PREMIUM_L_TESLA_R_YANFENG" 4 "PREMIUM_YANFENG" ;
VAL_ 2047 GTW_refrigACLineType 0 "UNLIMITED" 1 "SAAA_LIMITED" 2 "CONTI_LIMITED" ;
VAL_ 2047 GTW_restraintsHardwareType 101 "MXP2" 104 "MXP2_YOKE" 171 "MSP2" 174 "MSP2_YOKE" ;
VAL_ 2047 GTW_wheelType 25 "CARDENIO_19" 26 "NEW_TURBINE_22_BLACK" 28 "CYBERSTREAM_20" 29 "ARACHNID_21" ;
VAL_ 2047 GTW_efficiencyPackage 0 "DEFAULT" ;
VAL_ 2047 GTW_tpmsType 1 "TESLA_BLE" ;
VAL_ 2047 GTW_refrigFilterType 0 "UNBLOCKED" 1 "BLOCKED_V1" ;
VAL_ 2047 GTW_diBurnInType 0 "NONE" 1 "ENABLED_V1" ;
VAL_ 2047 GTW_pedestrianWarningSound 0 "NONE" 1 "SPEAKER" 2 "EXT_SPEAKER_V2" ;
VAL_ 2047 GTW_wirelessPhoneChargerType 2 "FRONT_AND_REAR_LIN" ;
VAL_ 2047 GTW_ethernetTunerType 0 "HARMAN" 1 "NONE" ;
VAL_ 2047 GTW_steeringColumnUJointType 0 "B_SAMPLE_PHASING" 1 "C_SAMPLE_PHASING" ;
VAL_ 2047 GTW_bPillarNFCParam 0 "3" 1 "Y" ;
VAL_ 2047 GTW_drivetrainType 1 "AWD" 2 "AWD_DUAL_REAR" ;
VAL_ 2047 GTW_interiorLighting 0 "BASE" 1 "PREMIUM" ;
VAL_ 2047 GTW_towPackage 0 "NONE" 1 "TESLA_REV1" ;
VAL_ 2047 GTW_headlightLevelerType 0 "NONE" 1 "GEN1" 2 "VIRTUAL_PITCH_SENSOR" ;
VAL_ 2047 GTW_interiorTrimType 0 "BLACK" 1 "WHITE" 4 "WALNUT_CREAM" 5 "WALNUT_WHITE" 6 "EBONY_BLACK" 7 "CARBON_CREAM" 8 "CARBON_WHITE" 9 "CARBON_BLACK" ;
VAL_ 2047 GTW_radarHeaterType 0 "NONE" 3 "MODELS_BACKER_THIN_3M" 4 "MODELX_BACKER_THIN_3M" ;
VAL_ 2047 GTW_steeringHeaterType 0 "NONE" 4 "ZF_ROUND" 5 "ZF_YOKE" ;
VAL_ 2047 GTW_numberHVILNodes 0 "0" 2 "2" 3 "3" ;
